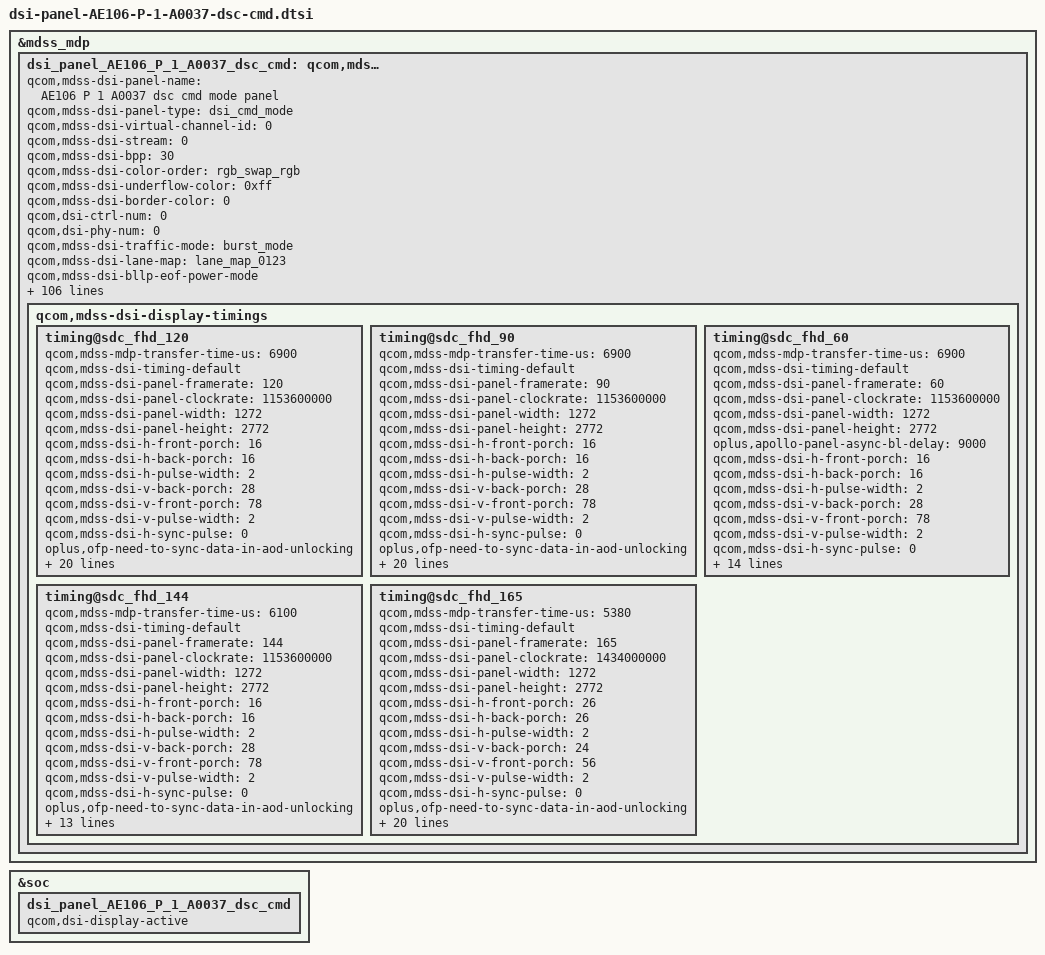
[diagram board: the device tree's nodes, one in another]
&mdss_mdp {
	dsi_panel_AE106_P_1_A0037_dsc_cmd: qcom,mdss_dsi_panel_AE106_P_1_A0037_dsc_cmd {
		qcom,mdss-dsi-panel-name = "AE106 P 1 A0037 dsc cmd mode panel";
		qcom,mdss-dsi-panel-type = "dsi_cmd_mode";
		qcom,mdss-dsi-virtual-channel-id = <0>;
		qcom,mdss-dsi-stream = <0>;
		qcom,mdss-dsi-bpp = <30>;
		qcom,mdss-dsi-color-order = "rgb_swap_rgb";
		qcom,mdss-dsi-underflow-color = <0xff>;
		qcom,mdss-dsi-border-color = <0>;
		qcom,dsi-ctrl-num = <0>;
		qcom,dsi-phy-num = <0>;
		qcom,mdss-dsi-traffic-mode = "burst_mode";
		qcom,mdss-dsi-lane-map = "lane_map_0123";
		qcom,mdss-dsi-bllp-eof-power-mode;
		qcom,mdss-dsi-bllp-power-mode;
		qcom,mdss-dsi-lane-0-state;
		qcom,mdss-dsi-lane-1-state;
		qcom,mdss-dsi-lane-2-state;
		qcom,mdss-dsi-lane-3-state;
		qcom,mdss-dsi-dma-trigger = "trigger_sw";
		qcom,mdss-dsi-dma-schedule-line = <1>;
		qcom,mdss-dsi-dma-schedule-window = <10>;
		qcom,mdss-dsi-mdp-trigger = "none";
		qcom,mdss-dsi-reset-sequence = <1 2>, <0 5>, <1 25>;
		qcom,mdss-dsi-te-pin-select = <1>;
		qcom,mdss-dsi-te-dcs-command = <1>;
		qcom,mdss-pan-physical-width-dimension = <71>;
		qcom,mdss-pan-physical-height-dimension = <157>;
		qcom,mdss-dsi-init-delay-us = <1000>;
		qcom,mdss-dsi-te-check-enable;
		qcom,mdss-dsi-te-using-te-pin;
		qcom,mdss-dsi-lp11-init;
		qcom,mdss-dsi-wr-mem-start = <0x2c>;
		qcom,mdss-dsi-wr-mem-continue = <0x3c>;
		qcom,mdss-dsi-panel-jitter = <0x4 0x1>;
		qcom,mdss-bl-high2bit;
		qcom,mdss-dsi-panel-skip-pps-update;
  		/* HDR Setting */
		qcom,mdss-dsi-panel-hdr-enabled;
		qcom,mdss-dsi-panel-hdr-color-primaries = <15635 16450 34000 16000 13250 34500 7500 3000>;
		//update for [MPC15]android.mediapc.cts.PerformanceClassTest#testDisplayHdr pass
		//qcom,mdss-dsi-panel-peak-brightness = <5400000>;
		qcom,mdss-dsi-panel-peak-brightness = <20000000>;
		qcom,mdss-dsi-panel-average-brightness = <2000000>;
		qcom,mdss-dsi-panel-blackness-level = <4000>;


		qcom,dynamic-mode-switch-enabled;
		qcom,dynamic-mode-switch-type = "dynamic-resolution-switch-immediate";
		qcom,mdss-dsi-display-timings {
			timing@sdc_fhd_120 {
				#include "dsi-panel-AE106-P-1-A0037-common.dtsi"
				#include "dsi-panel-AE106-P-1-A0037-common-effect.dtsi"
				qcom,mdss-mdp-transfer-time-us = <6900>;
				qcom,mdss-dsi-timing-default;
				qcom,mdss-dsi-panel-framerate = <120>;
				qcom,mdss-dsi-panel-clockrate = <1153600000>;
				qcom,mdss-dsi-panel-width = <1272>;
				qcom,mdss-dsi-panel-height = <2772>;

				qcom,mdss-dsi-h-front-porch = <16>;
				qcom,mdss-dsi-h-back-porch = <16>;
				qcom,mdss-dsi-h-pulse-width = <2>;
				qcom,mdss-dsi-v-back-porch = <28>;
				qcom,mdss-dsi-v-front-porch = <78>;
				qcom,mdss-dsi-v-pulse-width = <2>;
				qcom,mdss-dsi-h-sync-pulse = <0>;

				oplus,ofp-need-to-sync-data-in-aod-unlocking;
				oplus,ofp-aod-off-insert-black-frame = <1>;
				oplus,ofp-aod-off-black-frame-total-time = <42>;
				oplus,ofp-need-to-separate-backlight;
				oplus,ofp-backlight-on-period = <1>;

				qcom,mdss-dsi-timing-switch-command = [
				];
				qcom,mdss-dsi-fps-switch-60-to-120-command = [
					39 00 00 40 00 00 2D A9 01 00 44 26 27 00 00 01 00 44 28 2C 00 00 08 0B 18 02 01 C3 23 25 3F 5A 08 02 01 C3 26 27 3F 1A 02 01 C3 28 28 D4 02 01 C3 2E 2E 00
					39 00 00 40 00 00 B5 A9 02 08 E0 00 00 00 02 08 E1 02 02 20 02 08 E2 02 02 20 02 08 E1 10 10 24 02 08 E2 10 10 24 02 08 E1 1E 1E 1D 02 08 E2 1E 1E 1D 02 08 E1 2C 2C 18 02 08 E2 2C 2C 18 02 08 E1 3A 3A 10 02 08 E2 3A 3A 10 02 08 E3 3A 3A 04 02 08 E1 43 45 09 10 1A 02 08 E2 43 45 05 09 11 02 08 E3 43 45 05 0A 13 02 08 E1 48 48 08 02 08 E2 48 48 08 02 08 E3 48 48 04 02 08 E1 55 56 02 03 02 08 E2 56 56 04 02 08 E3 55 56 01 02 02 08 E1 64 64 03 02 08 E2 64 64 03 02 08 E3 62 64 01 02 03 02 08 E1 72 72 03 02 08 E2 72 72 03 02 08 E3 70 72 01 02 03 02 08 E0 00 00 01
					39 00 00 00 00 00 91 A9 01 00 68 00 00 00 02 01 DD 02 03 00 00 02 04 B5 01 03 00 00 03 01 00 9D 00 00 AA 02 08 B0 00 00 00 01 00 A2 00 47 13 02 09 BD 00 00 04 00 00 00 00 00 00 00 02 08 B7 20 27 08 00 08 00 07 B3 07 B3 02 08 B7 28 2D 07 CC 07 CC 08 00 00 00 02 08 B0 00 00 00 00 00 00 00 00 00 00 01 00 2F 00 00 00 00 00 00 00 00 00 00 02 01 B9 1C 1C 4A 01 00 8D 02 02 01 01 00 A3 00 0F 82 00 00 00 00 02 01 B9 1C 1C 4A 00 00 00 00 00 01 00 A3 10 11 00 00
				];
				qcom,mdss-dsi-fps-switch-90-to-120-command = [
					39 00 00 40 00 00 2D A9 01 00 44 26 27 00 00 01 00 44 28 2C 00 00 08 0B 18 02 01 C3 23 25 3F 5A 08 02 01 C3 26 27 3F 1A 02 01 C3 28 28 D4 02 01 C3 2E 2E 00
					39 00 00 40 00 00 B5 A9 02 08 E0 00 00 00 02 08 E1 02 02 20 02 08 E2 02 02 20 02 08 E1 10 10 24 02 08 E2 10 10 24 02 08 E1 1E 1E 1D 02 08 E2 1E 1E 1D 02 08 E1 2C 2C 18 02 08 E2 2C 2C 18 02 08 E1 3A 3A 10 02 08 E2 3A 3A 10 02 08 E3 3A 3A 04 02 08 E1 43 45 09 10 1A 02 08 E2 43 45 05 09 11 02 08 E3 43 45 05 0A 13 02 08 E1 48 48 08 02 08 E2 48 48 08 02 08 E3 48 48 04 02 08 E1 55 56 02 03 02 08 E2 56 56 04 02 08 E3 55 56 01 02 02 08 E1 64 64 03 02 08 E2 64 64 03 02 08 E3 62 64 01 02 03 02 08 E1 72 72 03 02 08 E2 72 72 03 02 08 E3 70 72 01 02 03 02 08 E0 00 00 01
					39 00 00 00 00 00 91 A9 01 00 68 00 00 00 02 01 DD 02 03 00 00 02 04 B5 01 03 00 00 03 01 00 9D 00 00 AA 02 08 B0 00 00 00 01 00 A2 00 47 13 02 09 BD 00 00 04 00 00 00 00 00 00 00 02 08 B7 20 27 08 00 08 00 07 B3 07 B3 02 08 B7 28 2D 07 CC 07 CC 08 00 00 00 02 08 B0 00 00 00 00 00 00 00 00 00 00 01 00 2F 00 00 00 00 00 00 00 00 00 00 02 01 B9 1C 1C 4A 01 00 8D 02 02 01 01 00 A3 00 0F 82 00 00 00 00 02 01 B9 1C 1C 4A 00 00 00 00 00 01 00 A3 10 11 00 00
				];
				qcom,mdss-dsi-fps-switch-144-to-120-command = [
					39 00 00 40 00 00 2D A9 01 00 44 26 27 00 00 01 00 44 28 2C 00 00 08 0B 18 02 01 C3 23 25 3F 5A 08 02 01 C3 26 27 3F 1A 02 01 C3 28 28 D4 02 01 C3 2E 2E 00
					39 00 00 40 00 00 B5 A9 02 08 E0 00 00 00 02 08 E1 02 02 20 02 08 E2 02 02 20 02 08 E1 10 10 24 02 08 E2 10 10 24 02 08 E1 1E 1E 1D 02 08 E2 1E 1E 1D 02 08 E1 2C 2C 18 02 08 E2 2C 2C 18 02 08 E1 3A 3A 10 02 08 E2 3A 3A 10 02 08 E3 3A 3A 04 02 08 E1 43 45 09 10 1A 02 08 E2 43 45 05 09 11 02 08 E3 43 45 05 0A 13 02 08 E1 48 48 08 02 08 E2 48 48 08 02 08 E3 48 48 04 02 08 E1 55 56 02 03 02 08 E2 56 56 04 02 08 E3 55 56 01 02 02 08 E1 64 64 03 02 08 E2 64 64 03 02 08 E3 62 64 01 02 03 02 08 E1 72 72 03 02 08 E2 72 72 03 02 08 E3 70 72 01 02 03 02 08 E0 00 00 01
					39 00 00 00 00 00 91 A9 01 00 68 00 00 00 02 01 DD 02 03 00 00 02 04 B5 01 03 00 00 03 01 00 9D 00 00 AA 02 08 B0 00 00 00 01 00 A2 00 47 13 02 09 BD 00 00 04 00 00 00 00 00 00 00 02 08 B7 20 27 08 00 08 00 07 B3 07 B3 02 08 B7 28 2D 07 CC 07 CC 08 00 00 00 02 08 B0 00 00 00 00 00 00 00 00 00 00 01 00 2F 00 00 00 00 00 00 00 00 00 00 02 01 B9 1C 1C 4A 01 00 8D 02 02 01 01 00 A3 00 0F 82 00 00 00 00 02 01 B9 1C 1C 4A 00 00 00 00 00 01 00 A3 10 11 00 00
				];
				qcom,mdss-dsi-fps-switch-165-to-120-command = [
					39 00 00 40 00 00 2D A9 01 00 44 26 27 00 00 01 00 44 28 2C 00 00 08 0B 18 02 01 C3 23 25 3F 5A 08 02 01 C3 26 27 3F 1A 02 01 C3 28 28 D4 02 01 C3 2E 2E 00
					39 00 00 40 00 00 B5 A9 02 08 E0 00 00 00 02 08 E1 02 02 20 02 08 E2 02 02 20 02 08 E1 10 10 24 02 08 E2 10 10 24 02 08 E1 1E 1E 1D 02 08 E2 1E 1E 1D 02 08 E1 2C 2C 18 02 08 E2 2C 2C 18 02 08 E1 3A 3A 10 02 08 E2 3A 3A 10 02 08 E3 3A 3A 04 02 08 E1 43 45 09 10 1A 02 08 E2 43 45 05 09 11 02 08 E3 43 45 05 0A 13 02 08 E1 48 48 08 02 08 E2 48 48 08 02 08 E3 48 48 04 02 08 E1 55 56 02 03 02 08 E2 56 56 04 02 08 E3 55 56 01 02 02 08 E1 64 64 03 02 08 E2 64 64 03 02 08 E3 62 64 01 02 03 02 08 E1 72 72 03 02 08 E2 72 72 03 02 08 E3 70 72 01 02 03 02 08 E0 00 00 01
					39 00 00 00 00 00 91 A9 01 00 68 00 00 00 02 01 DD 02 03 00 00 02 04 B5 01 03 00 00 03 01 00 9D 00 00 AA 02 08 B0 00 00 00 01 00 A2 00 47 13 02 09 BD 00 00 05 00 00 00 00 00 00 00 02 08 B7 20 27 08 00 08 00 07 B3 07 B3 02 08 B7 28 2D 07 CC 07 CC 08 00 00 00 02 08 B0 00 00 00 00 00 00 00 00 00 00 01 00 2F 00 00 00 00 00 00 00 00 00 00 02 01 B9 1C 1C 3A 01 00 8D 02 02 01 01 00 A3 00 0F 82 00 00 00 00 02 01 B9 1C 1C 4A 00 00 00 00 00 01 00 A3 10 11 00 00
				];
				qcom,mdss-dsi-on-command = [
					// Flash lock and reload
					39 00 00 40 00 00 06 F0 55 AA 52 08 04
					39 00 00 40 00 00 02 6F 03
					39 00 00 40 00 00 02 B5 0B
					39 00 00 40 00 00 02 C0 20
					39 00 00 40 00 00 02 C1 1C
					39 00 00 40 00 00 02 C0 80
					// DMR LUT SET
					39 00 00 40 00 00 02 C0 40
					39 00 00 40 00 00 06 F0 55 AA 52 08 00
					39 00 00 40 00 00 02 6F 31
					39 00 00 40 00 00 04 C0 01 02 10
					39 00 00 40 00 00 02 6F 08
					39 00 00 40 00 00 04 C7 98 97 80
					// APL BLK setting
					39 00 00 40 00 00 06 F0 55 AA 52 08 00
					39 00 00 40 00 00 02 6F 78
					39 00 00 40 00 00 18 B0 11 00 2A 00 C2 01 DA 03 7C 05 B1 08 80 0B EE 0F FF 05 55 05 56 05 55
					39 00 00 40 00 00 02 6F 6F
					39 00 00 40 00 00 07 B0 02 7C 04 F8 02 7C
					39 00 00 40 00 00 06 F0 55 AA 52 08 08
					39 00 00 40 00 00 17 C1 9D 4F DD 4F 4F DD 4F 4F DD 4F 4F DD 4F 4F BD 4F AC BB AC 9E 0D FF
					39 00 00 40 00 00 02 6F 1D
					39 00 00 40 00 00 04 C1 00 FF FF
					39 00 00 40 00 00 02 6F 20
					39 00 00 40 00 00 04 C1 3F 33 FF
					39 00 00 40 00 00 02 6F 23
					39 00 00 40 00 00 15 C1 0D 4F DD 4F 4F DD 4F 4F DD 4F 4F DD 4F 4F BD 4F AC BB AC 9E
					39 00 00 40 00 00 02 6F 37
					39 00 00 40 00 00 15 C1 0E FF EE FF FF EE FF FF EE FF FF EE FF FF DE FF 27 DD 27 27
					39 00 00 40 00 00 02 6F 4B
					39 00 00 40 00 00 15 C1 0D 4F DD 4F 4F DD 4F 4F DD 4F 4F DD 4F 4F BD 4F AC BB AC 9E
					39 00 00 40 00 00 02 6F 5F
					39 00 00 40 00 00 15 C1 0F FF FF FF FF FF FF FF FF FF FF FF FF FF FF FF FF FF FF FF
					39 00 00 40 00 00 02 6F 73
					39 00 00 40 00 00 15 C1 0D 4F DD 4F 4F DD 4F 4F DD 4F 4F DD 4F 4F BD 4F AC BB AC 9E
					39 00 00 40 00 00 2D BA 00 01 00 8A 00 8A 01 1E 01 1E 01 9D 01 9D 02 44 02 44 03 25 03 25 04 02 04 02 04 13 04 13 06 98 06 98 0A E2 0A E2 0D BB 0D BB 0F FE
					39 00 00 40 00 00 02 6F 07
					39 00 00 40 00 00 02 51 00
					39 00 00 40 00 00 05 FF AA 55 A5 80
					// Power on/off sequence related
					39 00 00 40 00 00 02 6F 08
					39 00 00 40 00 00 02 F6 54
					39 00 00 40 00 00 02 6F 0A
					39 00 00 40 00 00 07 F6 70 70 70 70 70 70
					// DMR flashing optimization
					39 00 00 40 00 00 05 FF AA 55 A5 81
					39 00 00 40 00 00 02 6F 0D
					39 00 00 40 00 00 02 FD 40
					// Charge Pump from 2uA to 4uA
					39 00 00 40 00 00 05 FF AA 55 A5 80
					39 00 00 40 00 00 02 6F 07
					39 00 00 40 00 00 02 F8 4D
					39 00 00 40 00 00 02 6F 23
					39 00 00 40 00 00 02 F8 4D
					// TE ON
					39 00 00 40 00 00 02 35 00
					//TE1F ON
					39 00 00 40 00 00 02 6F 15
					39 00 00 40 00 00 02 35 60
					39 00 00 40 00 00 02 6F 26
					39 00 00 40 00 00 08 44 00 00 00 00 08 0B 18
					// BC Dimming OFF
					39 00 00 40 00 00 02 53 20
					// Normal DBV setting
					39 00 00 40 00 00 03 51 00 00
					// Idle DBV Setting
					39 00 00 40 00 00 02 6F 04
					39 00 00 40 00 00 03 51 0D DA
					// H_res = 1272  V_res = 2772
					39 00 00 40 00 00 05 2A 00 00 04 F7
					39 00 00 40 00 00 05 2B 00 00 0A D3
					// Compression method selection 10_8 2dsc & slice high 12 & vesa 1.2
					39 00 00 40 00 00 02 90 03
					39 00 00 40 00 00 02 6F 01
					39 00 00 40 00 00 02 90 43
					39 00 00 40 00 00 13 91 AB A8 00 0C C2 00 02 3E 01 37 00 08 08 BB 07 32 10 F0
					// GPIO Setting
					39 00 00 40 00 00 06 F0 55 AA 52 08 00
					39 00 00 40 00 00 05 BE 5F 4C 47 49
					// Round curve control
					39 00 00 40 00 00 06 F0 55 AA 52 08 07
					39 00 00 40 00 00 0E B8 01 00 F5 09 C8 00 00 00 00 00 00 00 00
					39 00 00 40 00 00 04 C0 A7 01 09
					39 00 00 40 00 00 02 6F 03
					39 00 00 40 00 00 05 C0 00 00 00 00
					39 00 00 40 00 00 16 C1 B0 0F 00 24 09 00 FD C0 3F FF DD B0 3F FE 6D 28 00 00 08 2D 10
					39 00 00 40 00 00 02 6F 15
					39 00 00 40 00 00 11 C1 06 01 94 0E 00 00 06 33 F0 FA 86 02 DC 00 00 00
					39 00 00 40 00 00 02 6F 25
					39 00 00 40 00 00 08 C1 00 00 05 00 8A 98 00
					39 00 00 40 00 00 16 C2 B0 0F 26 49 29 71 B0 56 3F C1 8B B2 3F C0 4D 0A 00 17 08 B0 2C
					39 00 00 40 00 00 02 6F 15
					39 00 00 40 00 00 11 C2 3D 00 06 93 00 05 97 43 F0 6F 73 4F DD C0 00 FF
					39 00 00 40 00 00 02 6F 25
					39 00 00 40 00 00 08 C2 00 90 93 00 00 05 00
					39 00 00 40 00 00 16 C3 B8 0F 05 A4 00 10 FE D0 3F FF 44 E0 3F FF F0 28 00 00 03 97 B0
					39 00 00 40 00 00 02 6F 15
					39 00 00 40 00 00 11 C3 5A 00 00 06 00 98 F2 33 F0 A6 FA 02 1C 00 00 00
					39 00 00 40 00 00 02 6F 25
					39 00 00 40 00 00 08 C3 44 64 67 00 00 05 00
					39 00 00 40 00 00 16 C4 BC 00 13 24 00 40 04 60 3F FB 1E 00 00 00 00 00 00 00 00 00 00
					39 00 00 40 00 00 02 6F 15
					39 00 00 40 00 00 11 C4 82 00 00 08 9A CB 4D 33 C0 7E 08 00 00 00 00 00
					39 00 00 40 00 00 02 6F 25
					39 00 00 40 00 00 08 C4 44 F2 F7 00 91 97 00
					39 00 00 40 00 00 16 C5 BC 00 17 C4 1A E9 32 94 3F BD 81 A4 00 10 C8 E8 00 00 00 00 00
					39 00 00 40 00 00 02 6F 15
					39 00 00 40 00 00 11 C5 50 00 08 8F AA 4E CE 33 C0 80 87 00 00 00 00 00
					39 00 00 40 00 00 02 6F 25
					39 00 00 40 00 00 08 C5 00 01 07 AA 4D 57 00
					39 00 00 40 00 00 16 C6 B4 00 00 01 01 B9 00 2A 3F FF FC 58 00 00 12 48 00 00 00 00 00
					39 00 00 40 00 00 02 6F 15
					39 00 00 40 00 00 11 C6 05 00 90 C3 AA CE D3 33 C0 FB 33 00 00 00 00 00
					39 00 00 40 00 00 02 6F 25
					39 00 00 40 00 00 08 C6 00 88 90 AA CF D3 00
					39 00 00 40 00 00 16 C7 31 00 05 A4 05 A4 00 00 3F FE 53 50 3F FE 53 50 00 00 1F D1 10
					39 00 00 40 00 00 02 6F 15
					39 00 00 40 00 00 11 C7 0B 22 55 7B 00 2C 52 33 F0 DA DA 05 A4 00 00 00
					39 00 00 40 00 00 02 6F 25
					39 00 00 40 00 00 08 C7 44 F0 F7 AA 4D 54 00
					39 00 00 40 00 00 16 C8 3D 00 05 A4 05 A4 00 00 3F FE 53 50 00 00 00 00 00 00 00 00 00
					39 00 00 40 00 00 02 6F 15
					39 00 00 40 00 00 11 C8 1A 22 55 7B 00 53 79 33 C0 DA 26 00 00 00 00 00
					39 00 00 40 00 00 02 6F 25
					39 00 00 40 00 00 08 C8 44 69 70 AA CF D3 00
					39 00 00 40 00 00 16 C9 27 00 05 A4 05 A4 00 00 00 00 00 00 3F FE 53 50 00 00 00 00 00
					39 00 00 40 00 00 02 6F 15
					39 00 00 40 00 00 11 C9 0B 22 7C A2 00 2C 52 33 30 26 DA 00 00 00 00 00
					39 00 00 40 00 00 02 6F 25
					39 00 00 40 00 00 08 C9 00 00 00 00 00 00 00
					39 00 00 40 00 00 16 CA 2B 00 05 A4 05 A4 00 00 00 00 00 00 00 00 00 00 7F FF E0 2E F0
					39 00 00 40 00 00 02 6F 15
					39 00 00 40 00 00 11 CA 1A 22 7C A2 00 53 79 33 0F 26 26 FA 5C 00 00 00
					39 00 00 40 00 00 02 6F 25
					39 00 00 40 00 00 08 CA 00 00 00 00 00 00 00
					39 00 00 40 00 00 16 CB 00 00 00 00 00 00 00 00 00 00 00 00 00 00 00 00 00 00 00 00 00
					39 00 00 40 00 00 02 6F 15
					39 00 00 40 00 00 11 CB 00 00 00 00 00 00 00 00 00 00 00 00 00 00 00 00
					39 00 00 40 00 00 02 6F 25
					39 00 00 40 00 00 08 CB 00 00 00 00 00 00 00
					39 00 00 40 00 00 16 CC 00 00 00 00 00 00 00 00 00 00 00 00 00 00 00 00 00 00 00 00 00
					39 00 00 40 00 00 02 6F 15
					39 00 00 40 00 00 11 CC 00 00 00 00 00 00 00 00 00 00 00 00 00 00 00 00
					39 00 00 40 00 00 02 6F 25
					39 00 00 40 00 00 08 CC 00 00 00 00 00 00 00
					39 00 00 40 00 00 16 CD 00 00 00 00 00 00 00 00 00 00 00 00 00 00 00 00 00 00 00 00 00
					39 00 00 40 00 00 02 6F 15
					39 00 00 40 00 00 11 CD 00 00 00 00 00 00 00 00 00 00 00 00 00 00 00 00
					39 00 00 40 00 00 02 6F 25
					39 00 00 40 00 00 08 CD 00 00 00 00 00 00 00
					39 00 00 40 00 00 16 CE 00 00 00 00 00 00 00 00 00 00 00 00 00 00 00 00 00 00 00 00 00
					39 00 00 40 00 00 02 6F 15
					39 00 00 40 00 00 11 CE 00 00 00 00 00 00 00 00 00 00 00 00 00 00 00 00
					39 00 00 40 00 00 02 6F 25
					39 00 00 40 00 00 08 CE 00 00 00 00 00 00 00
					39 00 00 40 00 00 16 CF 00 00 00 00 00 00 00 00 00 00 00 00 00 00 00 00 00 00 00 00 00
					39 00 00 40 00 00 02 6F 15
					39 00 00 40 00 00 11 CF 00 00 00 00 00 00 00 00 00 00 00 00 00 00 00 00
					39 00 00 40 00 00 02 6F 25
					39 00 00 40 00 00 08 CF 00 00 00 00 00 00 00
					39 00 00 40 00 00 16 D0 00 00 00 00 00 00 00 00 00 00 00 00 00 00 00 00 00 00 00 00 00
					39 00 00 40 00 00 02 6F 15
					39 00 00 40 00 00 11 D0 00 00 00 00 00 00 00 00 00 00 00 00 00 00 00 00
					39 00 00 40 00 00 02 6F 25
					39 00 00 40 00 00 08 D0 00 00 00 00 00 00 00
					39 00 00 40 00 00 0F D1 80 00 00 00 00 04 F8 80 00 6B BD 09 04 F7
					39 00 00 40 00 00 02 6F 0E
					39 00 00 40 00 00 0F D1 80 00 00 00 00 04 F7 FF FF DD B9 00 04 F7
					39 00 00 40 00 00 02 6F 1C
					39 00 00 40 00 00 0F D1 FF E3 8B 46 00 04 F7 FF FF FF 4F B1 04 F8
					39 00 00 40 00 00 02 6F 2A
					39 00 00 40 00 00 0C D1 00 00 00 00 00 04 F8 7F FF E0 2E
					39 00 00 40 00 00 12 D2 F0 04 F8 00 00 1F D1 10 04 F8 00 00 00 00 00 04 F8
					//RCN
					39 00 00 40 00 00 06 F0 55 AA 52 08 07
					39 00 00 40 00 00 02 C0 A7
					//OSC trim
					39 00 00 40 00 00 06 F0 55 AA 52 08 01
					39 00 00 40 00 00 36 C3 99 29 02 6B 19 00 29 00 6B 19 00 3F 5A 08 3F 1A D4 3F 2A 07 3F 28 D4 3F 25 06 3F 61 D4 3F 3B 46 3F 46 07 3F 5A 08 3F 1A D4 11 11 01 00 10 00 77 00 AA 02 AA 02
					39 00 00 40 00 00 06 F0 55 AA 52 08 01
					39 00 00 40 00 00 07 B3 44 44 44 44 44 44
					39 00 00 40 00 00 06 F0 55 AA 52 08 07
					39 00 00 40 00 00 0E B4 C0 50 60 60 50 35 80 20 60 58 80 38 70
					//OD
					39 00 00 40 00 00 06 F0 55 AA 52 08 08
					39 00 00 40 00 00 05 E0 01 01 81 01
					39 00 00 40 00 00 02 6F 06
					39 00 00 40 00 00 0E E0 80 00 21 32 43 54 65 66 66 76 87 98 99
					39 00 00 40 00 00 06 F0 55 AA 52 08 08
					39 00 00 40 00 00 02 6F 04
					39 00 00 40 00 00 02 E0 20
					39 00 00 40 00 00 02 6F 1B
					39 00 00 40 00 00 04 EB 44 00 00
					39 00 00 40 00 00 02 6F 1E
					39 00 00 40 00 00 04 EB 94 00 00
					39 00 00 40 00 00 02 6F 21
					39 00 00 40 00 00 03 EB 04 00
					39 00 00 40 00 00 02 6F 24
					39 00 00 40 00 00 04 EB 10 32 54
					39 00 00 40 00 00 0F E1 03 04 20 00 00 00 00 00 00 00 00 00 00 00
					39 00 00 40 00 00 0F E2 03 04 20 00 00 00 00 00 00 00 00 00 00 00
					39 00 00 40 00 00 0F E3 00 00 00 00 00 00 00 00 00 00 00 00 00 00
					39 00 00 40 00 00 02 6F 0E
					39 00 00 40 00 00 0F E1 02 04 24 03 03 03 03 03 03 03 03 08 0F 1A
					39 00 00 40 00 00 02 6F 0E
					39 00 00 40 00 00 0F E2 03 04 24 03 03 03 03 03 03 03 03 09 0E 17
					39 00 00 40 00 00 02 6F 0E
					39 00 00 40 00 00 0F E3 03 04 06 03 03 03 03 03 03 04 03 09 0E 07
					39 00 00 40 00 00 02 6F 1C
					39 00 00 40 00 00 0F E1 01 03 1D 03 03 03 03 03 03 03 03 03 08 0F
					39 00 00 40 00 00 02 6F 1C
					39 00 00 40 00 00 0F E2 02 03 1D 04 04 04 04 04 04 04 04 04 07 0C
					39 00 00 40 00 00 02 6F 1C
					39 00 00 40 00 00 0F E3 02 03 05 04 04 04 04 04 04 04 04 03 07 12
					39 00 00 40 00 00 02 6F 2A
					39 00 00 40 00 00 0F E1 01 03 18 04 04 04 04 04 04 04 04 04 07 0E
					39 00 00 40 00 00 02 6F 2A
					39 00 00 40 00 00 0F E2 02 03 18 03 03 03 03 03 03 03 03 03 06 0D
					39 00 00 40 00 00 02 6F 2A
					39 00 00 40 00 00 0F E3 01 01 04 03 03 03 03 03 03 03 03 05 0B 13
					39 00 00 40 00 00 02 6F 38
					39 00 00 40 00 00 0F E1 02 04 10 04 04 04 04 04 04 04 04 09 10 1A
					39 00 00 40 00 00 02 6F 38
					39 00 00 40 00 00 0F E2 03 04 10 04 04 04 04 04 04 04 04 05 09 11
					39 00 00 40 00 00 02 6F 38
					39 00 00 40 00 00 0F E3 01 01 04 04 04 04 04 04 04 04 05 05 0A 13
					39 00 00 40 00 00 02 6F 46
					39 00 00 40 00 00 0F E1 02 04 08 03 03 03 03 03 05 05 05 05 05 10
					39 00 00 40 00 00 02 6F 46
					39 00 00 40 00 00 0F E2 03 04 08 03 03 03 03 03 04 04 04 04 04 06
					39 00 00 40 00 00 02 6F 46
					39 00 00 40 00 00 0F E3 01 01 04 03 03 03 03 03 04 04 04 04 04 06
					39 00 00 40 00 00 02 6F 54
					39 00 00 40 00 00 0F E1 01 02 03 04 05 05 05 03 03 03 02 02 02 02
					39 00 00 40 00 00 02 6F 54
					39 00 00 40 00 00 0F E2 01 02 04 04 04 05 05 02 02 01 01 01 01 01
					39 00 00 40 00 00 02 6F 54
					39 00 00 40 00 00 0F E3 00 01 02 02 04 05 05 02 02 01 01 01 01 01
					39 00 00 40 00 00 02 6F 62
					39 00 00 40 00 00 0F E1 01 02 03 04 04 04 04 03 03 03 02 02 02 02
					39 00 00 40 00 00 02 6F 62
					39 00 00 40 00 00 0F E2 01 02 03 03 03 03 03 02 02 01 01 01 01 01
					39 00 00 40 00 00 02 6F 62
					39 00 00 40 00 00 0F E3 01 02 03 03 03 03 03 02 02 01 01 01 01 01
					39 00 00 40 00 00 02 6F 70
					39 00 00 40 00 00 0F E1 01 02 03 04 04 04 04 03 03 03 02 02 02 02
					39 00 00 40 00 00 02 6F 70
					39 00 00 40 00 00 0F E2 01 02 03 04 05 04 04 02 02 02 01 01 01 01
					39 00 00 40 00 00 02 6F 70
					39 00 00 40 00 00 0F E3 01 02 03 04 05 04 04 02 02 02 01 01 01 01
					// Sleep out
					15 00 00 00 78 00 02 11 00
					// Display on
					15 00 00 00 00 00 02 29 00
					39 00 00 40 00 00 02 68 00
					39 00 00 40 00 00 06 F0 55 AA 52 08 00
					39 00 00 40 00 00 02 6F 04
					39 00 00 40 00 00 02 B1 00
					39 00 00 40 00 00 02 6F 2A
					39 00 00 40 00 00 02 BB 00
					39 00 00 40 00 00 02 6F 30
					39 00 00 40 00 00 02 C0 3F
					39 00 00 40 00 00 06 F0 55 AA 52 08 09
					39 00 00 40 00 00 02 BD 04
					39 00 00 40 00 00 02 6F 01
					39 00 00 40 00 00 0A BD 31 9D 25 54 13 14 A6 98 E2
					39 00 00 40 00 00 02 6F 0A
					39 00 00 40 00 00 06 BD 10 20 40 80 FF
					39 00 00 40 00 00 02 6F 1A
					39 00 00 40 00 00 06 BD FF FF FF FF FF
					39 00 00 40 00 00 02 6F 10
					39 00 00 40 00 00 04 BD FD 07 00
					39 00 00 40 00 00 02 6F 16
					39 00 00 40 00 00 02 BD 15
					39 00 00 40 00 00 06 F0 55 AA 52 08 09
					39 00 00 40 00 00 02 6F 00
					39 00 00 40 00 00 1F BE 19 14 0A 23 1E 05 05 00 05 0A 01 01 03 06 82 00 02 02 00 09 81 02 80 88 0B 01 00 00 07 81
					39 00 00 40 00 00 02 6F 1E
					39 00 00 40 00 00 1F BE 19 14 0A 23 1E 05 05 00 05 0A 01 01 03 06 82 00 02 02 00 09 81 02 80 88 0B 01 00 00 07 81
					39 00 00 40 00 00 02 6F 3C
					39 00 00 40 00 00 1F BE 19 14 0A 23 1E 05 05 00 05 0A 01 01 03 06 82 00 02 02 00 09 81 02 80 88 0B 01 00 00 07 81
					39 00 00 40 00 00 06 F0 55 AA 52 08 09
					39 00 00 40 00 00 02 6F 00
					39 00 00 40 00 00 1F BF 19 18 0C 18 2C 08 02 02 0A 04 04 04 10 08 14 01 04 06 00 0C 00 00 04 89 88 02 02 05 02 0A
					39 00 00 40 00 00 02 6F 1E
					39 00 00 40 00 00 1F BF 19 18 0C 18 2C 08 02 02 0A 04 04 04 10 08 14 01 04 06 00 0C 00 00 04 89 88 02 02 05 02 0A
					39 00 00 40 00 00 02 6F 3C
					39 00 00 40 00 00 1F BF 19 18 0C 18 2C 08 02 02 0A 04 04 04 10 08 14 01 04 06 00 0C 00 00 04 89 88 02 02 05 02 0A
					// 120Hz Freq. Setting
					39 00 00 40 00 00 2D A9 01 00 44 26 27 00 00 01 00 44 28 2C 00 00 08 0B 18 02 01 C3 23 25 3F 5A 08 02 01 C3 26 27 3F 1A 02 01 C3 28 28 D4 02 01 C3 2E 2E 00
					39 00 00 40 00 00 B5 A9 02 08 E0 00 00 00 02 08 E1 02 02 20 02 08 E2 02 02 20 02 08 E1 10 10 24 02 08 E2 10 10 24 02 08 E1 1E 1E 1D 02 08 E2 1E 1E 1D 02 08 E1 2C 2C 18 02 08 E2 2C 2C 18 02 08 E1 3A 3A 10 02 08 E2 3A 3A 10 02 08 E3 3A 3A 04 02 08 E1 43 45 09 10 1A 02 08 E2 43 45 05 09 11 02 08 E3 43 45 05 0A 13 02 08 E1 48 48 08 02 08 E2 48 48 08 02 08 E3 48 48 04 02 08 E1 55 56 02 03 02 08 E2 56 56 04 02 08 E3 55 56 01 02 02 08 E1 64 64 03 02 08 E2 64 64 03 02 08 E3 62 64 01 02 03 02 08 E1 72 72 03 02 08 E2 72 72 03 02 08 E3 70 72 01 02 03 02 08 E0 00 00 01
					39 00 00 00 00 00 91 A9 01 00 68 00 00 00 02 01 DD 02 03 00 00 02 04 B5 01 03 00 00 03 01 00 9D 00 00 AA 02 08 B0 00 00 00 01 00 A2 00 47 13 02 09 BD 00 00 04 00 00 00 00 00 00 00 02 08 B7 20 27 08 00 08 00 07 B3 07 B3 02 08 B7 28 2D 07 CC 07 CC 08 00 00 00 02 08 B0 00 00 00 00 00 00 00 00 00 00 01 00 2F 00 00 00 00 00 00 00 00 00 00 02 01 B9 1C 1C 4A 01 00 8D 02 02 01 01 00 A3 00 0F 82 00 00 00 00 02 01 B9 1C 1C 4A 00 00 00 00 00 01 00 A3 10 11 00 00
				];

			};
			timing@sdc_fhd_90 {
				#include "dsi-panel-AE106-P-1-A0037-common.dtsi"
				#include "dsi-panel-AE106-P-1-A0037-common-effect.dtsi"
				qcom,mdss-mdp-transfer-time-us = <6900>;
				qcom,mdss-dsi-timing-default;
				qcom,mdss-dsi-panel-framerate = <90>;
				qcom,mdss-dsi-panel-clockrate = <1153600000>;
				qcom,mdss-dsi-panel-width = <1272>;
				qcom,mdss-dsi-panel-height = <2772>;

				qcom,mdss-dsi-h-front-porch = <16>;
				qcom,mdss-dsi-h-back-porch = <16>;
				qcom,mdss-dsi-h-pulse-width = <2>;
				qcom,mdss-dsi-v-back-porch = <28>;
				qcom,mdss-dsi-v-front-porch = <78>;
				qcom,mdss-dsi-v-pulse-width = <2>;
				qcom,mdss-dsi-h-sync-pulse = <0>;

				oplus,ofp-need-to-sync-data-in-aod-unlocking;
				oplus,ofp-aod-off-insert-black-frame = <1>;
				oplus,ofp-aod-off-black-frame-total-time = <42>;
				oplus,ofp-need-to-separate-backlight;
				oplus,ofp-backlight-on-period = <1>;

				qcom,mdss-dsi-timing-switch-command = [
				];
				qcom,mdss-dsi-fps-switch-60-to-90-command = [
					39 00 00 40 00 00 2D A9 01 00 44 26 27 00 00 01 00 44 28 2C 00 00 08 07 60 02 01 C3 23 25 3F 2A 07 02 01 C3 26 27 3F 28 02 01 C3 28 28 D4 02 01 C3 2E 2E 00
					39 00 00 40 00 00 B5 A9 02 08 E0 00 00 00 02 08 E1 02 02 20 02 08 E2 02 02 20 02 08 E1 10 10 24 02 08 E2 10 10 24 02 08 E1 1E 1E 1D 02 08 E2 1E 1E 1D 02 08 E1 2C 2C 18 02 08 E2 2C 2C 18 02 08 E1 3A 3A 10 02 08 E2 3A 3A 10 02 08 E3 3A 3A 04 02 08 E1 43 45 09 10 1A 02 08 E2 43 45 05 09 11 02 08 E3 43 45 05 0A 13 02 08 E1 48 48 08 02 08 E2 48 48 08 02 08 E3 48 48 04 02 08 E1 55 56 02 03 02 08 E2 56 56 04 02 08 E3 55 56 01 02 02 08 E1 64 64 03 02 08 E2 64 64 03 02 08 E3 62 64 01 02 03 02 08 E1 72 72 03 02 08 E2 72 72 03 02 08 E3 70 72 01 02 03 02 08 E0 00 00 01
					39 00 00 00 00 00 91 A9 01 00 68 00 00 00 02 01 DD 02 03 00 00 02 04 B5 01 03 00 00 03 01 00 9D 00 00 AA 02 08 B0 00 00 00 01 00 A2 00 47 13 02 09 BD 00 00 04 00 00 00 00 00 00 00 02 08 B7 20 27 08 00 08 00 07 B3 07 B3 02 08 B7 28 2D 07 CC 07 CC 08 00 00 00 02 08 B0 00 00 00 00 00 00 00 00 00 00 01 00 2F 00 00 01 00 00 00 00 00 00 00 02 01 B9 1D 1D 4A 01 00 8D 02 02 01 01 00 A3 00 0F 82 00 00 00 00 02 01 B9 1D 1D 4A 00 00 00 00 00 01 00 A3 10 11 00 00
				];
				qcom,mdss-dsi-fps-switch-120-to-90-command = [
					39 00 00 40 00 00 2D A9 01 00 44 26 27 00 00 01 00 44 28 2C 00 00 08 07 60 02 01 C3 23 25 3F 2A 07 02 01 C3 26 27 3F 28 02 01 C3 28 28 D4 02 01 C3 2E 2E 00
					39 00 00 40 00 00 B5 A9 02 08 E0 00 00 00 02 08 E1 02 02 20 02 08 E2 02 02 20 02 08 E1 10 10 24 02 08 E2 10 10 24 02 08 E1 1E 1E 1D 02 08 E2 1E 1E 1D 02 08 E1 2C 2C 18 02 08 E2 2C 2C 18 02 08 E1 3A 3A 10 02 08 E2 3A 3A 10 02 08 E3 3A 3A 04 02 08 E1 43 45 09 10 1A 02 08 E2 43 45 05 09 11 02 08 E3 43 45 05 0A 13 02 08 E1 48 48 08 02 08 E2 48 48 08 02 08 E3 48 48 04 02 08 E1 55 56 02 03 02 08 E2 56 56 04 02 08 E3 55 56 01 02 02 08 E1 64 64 03 02 08 E2 64 64 03 02 08 E3 62 64 01 02 03 02 08 E1 72 72 03 02 08 E2 72 72 03 02 08 E3 70 72 01 02 03 02 08 E0 00 00 01
					39 00 00 00 00 00 91 A9 01 00 68 00 00 00 02 01 DD 02 03 00 00 02 04 B5 01 03 00 00 03 01 00 9D 00 00 AA 02 08 B0 00 00 00 01 00 A2 00 47 13 02 09 BD 00 00 04 00 00 00 00 00 00 00 02 08 B7 20 27 08 00 08 00 07 B3 07 B3 02 08 B7 28 2D 07 CC 07 CC 08 00 00 00 02 08 B0 00 00 00 00 00 00 00 00 00 00 01 00 2F 00 00 01 00 00 00 00 00 00 00 02 01 B9 1D 1D 4A 01 00 8D 02 02 01 01 00 A3 00 0F 82 00 00 00 00 02 01 B9 1D 1D 4A 00 00 00 00 00 01 00 A3 10 11 00 00
				];
				qcom,mdss-dsi-fps-switch-144-to-90-command = [
					39 00 00 40 00 00 2D A9 01 00 44 26 27 00 00 01 00 44 28 2C 00 00 08 07 60 02 01 C3 23 25 3F 2A 07 02 01 C3 26 27 3F 28 02 01 C3 28 28 D4 02 01 C3 2E 2E 00
					39 00 00 40 00 00 B5 A9 02 08 E0 00 00 00 02 08 E1 02 02 20 02 08 E2 02 02 20 02 08 E1 10 10 24 02 08 E2 10 10 24 02 08 E1 1E 1E 1D 02 08 E2 1E 1E 1D 02 08 E1 2C 2C 18 02 08 E2 2C 2C 18 02 08 E1 3A 3A 10 02 08 E2 3A 3A 10 02 08 E3 3A 3A 04 02 08 E1 43 45 09 10 1A 02 08 E2 43 45 05 09 11 02 08 E3 43 45 05 0A 13 02 08 E1 48 48 08 02 08 E2 48 48 08 02 08 E3 48 48 04 02 08 E1 55 56 02 03 02 08 E2 56 56 04 02 08 E3 55 56 01 02 02 08 E1 64 64 03 02 08 E2 64 64 03 02 08 E3 62 64 01 02 03 02 08 E1 72 72 03 02 08 E2 72 72 03 02 08 E3 70 72 01 02 03 02 08 E0 00 00 01
					39 00 00 00 00 00 91 A9 01 00 68 00 00 00 02 01 DD 02 03 00 00 02 04 B5 01 03 00 00 03 01 00 9D 00 00 AA 02 08 B0 00 00 00 01 00 A2 00 47 13 02 09 BD 00 00 04 00 00 00 00 00 00 00 02 08 B7 20 27 08 00 08 00 07 B3 07 B3 02 08 B7 28 2D 07 CC 07 CC 08 00 00 00 02 08 B0 00 00 00 00 00 00 00 00 00 00 01 00 2F 00 00 01 00 00 00 00 00 00 00 02 01 B9 1D 1D 4A 01 00 8D 02 02 01 01 00 A3 00 0F 82 00 00 00 00 02 01 B9 1D 1D 4A 00 00 00 00 00 01 00 A3 10 11 00 00
				];
				qcom,mdss-dsi-fps-switch-165-to-90-command = [
					39 00 00 40 00 00 2D A9 01 00 44 26 27 00 00 01 00 44 28 2C 00 00 08 07 60 02 01 C3 23 25 3F 2A 07 02 01 C3 26 27 3F 28 02 01 C3 28 28 D4 02 01 C3 2E 2E 00
					39 00 00 40 00 00 B5 A9 02 08 E0 00 00 00 02 08 E1 02 02 20 02 08 E2 02 02 20 02 08 E1 10 10 24 02 08 E2 10 10 24 02 08 E1 1E 1E 1D 02 08 E2 1E 1E 1D 02 08 E1 2C 2C 18 02 08 E2 2C 2C 18 02 08 E1 3A 3A 10 02 08 E2 3A 3A 10 02 08 E3 3A 3A 04 02 08 E1 43 45 09 10 1A 02 08 E2 43 45 05 09 11 02 08 E3 43 45 05 0A 13 02 08 E1 48 48 08 02 08 E2 48 48 08 02 08 E3 48 48 04 02 08 E1 55 56 02 03 02 08 E2 56 56 04 02 08 E3 55 56 01 02 02 08 E1 64 64 03 02 08 E2 64 64 03 02 08 E3 62 64 01 02 03 02 08 E1 72 72 03 02 08 E2 72 72 03 02 08 E3 70 72 01 02 03 02 08 E0 00 00 01
					39 00 00 00 00 00 91 A9 01 00 68 00 00 30 02 01 DD 02 03 00 00 02 04 B5 01 03 00 00 03 01 00 9D 00 00 AA 02 08 B0 00 00 00 01 00 A2 00 47 13 02 09 BD 00 00 05 00 00 00 00 00 00 00 02 08 B7 20 27 08 00 08 00 07 B3 07 B3 02 08 B7 28 2D 07 CC 07 CC 08 00 00 00 02 08 B0 00 00 00 00 00 00 00 00 00 00 01 00 2F 00 00 01 00 00 00 00 00 00 00 02 01 B9 1D 1D 3A 01 00 8D 02 02 01 01 00 A3 00 0F 82 00 00 00 00 02 01 B9 1D 1D 4A 00 00 00 00 00 01 00 A3 10 11 00 00
				];
				qcom,mdss-dsi-on-command = [
					// Flash lock and reload
					39 00 00 40 00 00 06 F0 55 AA 52 08 04
					39 00 00 40 00 00 02 6F 03
					39 00 00 40 00 00 02 B5 0B
					39 00 00 40 00 00 02 C0 20
					39 00 00 40 00 00 02 C1 1C
					39 00 00 40 00 00 02 C0 80
					// DMR LUT SET
					39 00 00 40 00 00 02 C0 40
					39 00 00 40 00 00 06 F0 55 AA 52 08 00
					39 00 00 40 00 00 02 6F 31
					39 00 00 40 00 00 04 C0 01 02 10
					39 00 00 40 00 00 02 6F 08
					39 00 00 40 00 00 04 C7 98 97 80
					// APL BLK setting
					39 00 00 40 00 00 06 F0 55 AA 52 08 00
					39 00 00 40 00 00 02 6F 78
					39 00 00 40 00 00 18 B0 11 00 2A 00 C2 01 DA 03 7C 05 B1 08 80 0B EE 0F FF 05 55 05 56 05 55
					39 00 00 40 00 00 02 6F 6F
					39 00 00 40 00 00 07 B0 02 7C 04 F8 02 7C
					39 00 00 40 00 00 06 F0 55 AA 52 08 08
					39 00 00 40 00 00 17 C1 9D 4F DD 4F 4F DD 4F 4F DD 4F 4F DD 4F 4F BD 4F AC BB AC 9E 0D FF
					39 00 00 40 00 00 02 6F 1D
					39 00 00 40 00 00 04 C1 00 FF FF
					39 00 00 40 00 00 02 6F 20
					39 00 00 40 00 00 04 C1 3F 33 FF
					39 00 00 40 00 00 02 6F 23
					39 00 00 40 00 00 15 C1 0D 4F DD 4F 4F DD 4F 4F DD 4F 4F DD 4F 4F BD 4F AC BB AC 9E
					39 00 00 40 00 00 02 6F 37
					39 00 00 40 00 00 15 C1 0E FF EE FF FF EE FF FF EE FF FF EE FF FF DE FF 27 DD 27 27
					39 00 00 40 00 00 02 6F 4B
					39 00 00 40 00 00 15 C1 0D 4F DD 4F 4F DD 4F 4F DD 4F 4F DD 4F 4F BD 4F AC BB AC 9E
					39 00 00 40 00 00 02 6F 5F
					39 00 00 40 00 00 15 C1 0F FF FF FF FF FF FF FF FF FF FF FF FF FF FF FF FF FF FF FF
					39 00 00 40 00 00 02 6F 73
					39 00 00 40 00 00 15 C1 0D 4F DD 4F 4F DD 4F 4F DD 4F 4F DD 4F 4F BD 4F AC BB AC 9E
					39 00 00 40 00 00 2D BA 00 01 00 8A 00 8A 01 1E 01 1E 01 9D 01 9D 02 44 02 44 03 25 03 25 04 02 04 02 04 13 04 13 06 98 06 98 0A E2 0A E2 0D BB 0D BB 0F FE
					39 00 00 40 00 00 02 6F 07
					39 00 00 40 00 00 02 51 00
					39 00 00 40 00 00 05 FF AA 55 A5 80
					// Power on/off sequence related
					39 00 00 40 00 00 02 6F 08
					39 00 00 40 00 00 02 F6 54
					39 00 00 40 00 00 02 6F 0A
					39 00 00 40 00 00 07 F6 70 70 70 70 70 70
					// DMR flashing optimization
					39 00 00 40 00 00 05 FF AA 55 A5 81
					39 00 00 40 00 00 02 6F 0D
					39 00 00 40 00 00 02 FD 40
					// Charge Pump from 2uA to 4uA
					39 00 00 40 00 00 05 FF AA 55 A5 80
					39 00 00 40 00 00 02 6F 07
					39 00 00 40 00 00 02 F8 4D
					39 00 00 40 00 00 02 6F 23
					39 00 00 40 00 00 02 F8 4D
					// TE ON
					39 00 00 40 00 00 02 35 00
					//TE1F ON
					39 00 00 40 00 00 02 6F 15
					39 00 00 40 00 00 02 35 60
					39 00 00 40 00 00 02 6F 26
					39 00 00 40 00 00 08 44 00 00 00 00 08 07 60
					// BC Dimming OFF
					39 00 00 40 00 00 02 53 20
					// Normal DBV setting
					39 00 00 40 00 00 03 51 00 00
					// Idle DBV Setting
					39 00 00 40 00 00 02 6F 04
					39 00 00 40 00 00 03 51 0D DA
					// H_res = 1272  V_res = 2772
					39 00 00 40 00 00 05 2A 00 00 04 F7
					39 00 00 40 00 00 05 2B 00 00 0A D3
					// Compression method selection 10_8 2dsc & slice high 12 & vesa 1.2
					39 00 00 40 00 00 02 90 03
					39 00 00 40 00 00 02 6F 01
					39 00 00 40 00 00 02 90 43
					39 00 00 40 00 00 13 91 AB A8 00 0C C2 00 02 3E 01 37 00 08 08 BB 07 32 10 F0
					// GPIO Setting
					39 00 00 40 00 00 06 F0 55 AA 52 08 00
					39 00 00 40 00 00 05 BE 5F 4C 47 49
					// Round curve control
					39 00 00 40 00 00 06 F0 55 AA 52 08 07
					39 00 00 40 00 00 0E B8 01 00 F5 09 C8 00 00 00 00 00 00 00 00
					39 00 00 40 00 00 04 C0 A7 01 09
					39 00 00 40 00 00 02 6F 03
					39 00 00 40 00 00 05 C0 00 00 00 00
					39 00 00 40 00 00 16 C1 B0 0F 00 24 09 00 FD C0 3F FF DD B0 3F FE 6D 28 00 00 08 2D 10
					39 00 00 40 00 00 02 6F 15
					39 00 00 40 00 00 11 C1 06 01 94 0E 00 00 06 33 F0 FA 86 02 DC 00 00 00
					39 00 00 40 00 00 02 6F 25
					39 00 00 40 00 00 08 C1 00 00 05 00 8A 98 00
					39 00 00 40 00 00 16 C2 B0 0F 26 49 29 71 B0 56 3F C1 8B B2 3F C0 4D 0A 00 17 08 B0 2C
					39 00 00 40 00 00 02 6F 15
					39 00 00 40 00 00 11 C2 3D 00 06 93 00 05 97 43 F0 6F 73 4F DD C0 00 FF
					39 00 00 40 00 00 02 6F 25
					39 00 00 40 00 00 08 C2 00 90 93 00 00 05 00
					39 00 00 40 00 00 16 C3 B8 0F 05 A4 00 10 FE D0 3F FF 44 E0 3F FF F0 28 00 00 03 97 B0
					39 00 00 40 00 00 02 6F 15
					39 00 00 40 00 00 11 C3 5A 00 00 06 00 98 F2 33 F0 A6 FA 02 1C 00 00 00
					39 00 00 40 00 00 02 6F 25
					39 00 00 40 00 00 08 C3 44 64 67 00 00 05 00
					39 00 00 40 00 00 16 C4 BC 00 13 24 00 40 04 60 3F FB 1E 00 00 00 00 00 00 00 00 00 00
					39 00 00 40 00 00 02 6F 15
					39 00 00 40 00 00 11 C4 82 00 00 08 9A CB 4D 33 C0 7E 08 00 00 00 00 00
					39 00 00 40 00 00 02 6F 25
					39 00 00 40 00 00 08 C4 44 F2 F7 00 91 97 00
					39 00 00 40 00 00 16 C5 BC 00 17 C4 1A E9 32 94 3F BD 81 A4 00 10 C8 E8 00 00 00 00 00
					39 00 00 40 00 00 02 6F 15
					39 00 00 40 00 00 11 C5 50 00 08 8F AA 4E CE 33 C0 80 87 00 00 00 00 00
					39 00 00 40 00 00 02 6F 25
					39 00 00 40 00 00 08 C5 00 01 07 AA 4D 57 00
					39 00 00 40 00 00 16 C6 B4 00 00 01 01 B9 00 2A 3F FF FC 58 00 00 12 48 00 00 00 00 00
					39 00 00 40 00 00 02 6F 15
					39 00 00 40 00 00 11 C6 05 00 90 C3 AA CE D3 33 C0 FB 33 00 00 00 00 00
					39 00 00 40 00 00 02 6F 25
					39 00 00 40 00 00 08 C6 00 88 90 AA CF D3 00
					39 00 00 40 00 00 16 C7 31 00 05 A4 05 A4 00 00 3F FE 53 50 3F FE 53 50 00 00 1F D1 10
					39 00 00 40 00 00 02 6F 15
					39 00 00 40 00 00 11 C7 0B 22 55 7B 00 2C 52 33 F0 DA DA 05 A4 00 00 00
					39 00 00 40 00 00 02 6F 25
					39 00 00 40 00 00 08 C7 44 F0 F7 AA 4D 54 00
					39 00 00 40 00 00 16 C8 3D 00 05 A4 05 A4 00 00 3F FE 53 50 00 00 00 00 00 00 00 00 00
					39 00 00 40 00 00 02 6F 15
					39 00 00 40 00 00 11 C8 1A 22 55 7B 00 53 79 33 C0 DA 26 00 00 00 00 00
					39 00 00 40 00 00 02 6F 25
					39 00 00 40 00 00 08 C8 44 69 70 AA CF D3 00
					39 00 00 40 00 00 16 C9 27 00 05 A4 05 A4 00 00 00 00 00 00 3F FE 53 50 00 00 00 00 00
					39 00 00 40 00 00 02 6F 15
					39 00 00 40 00 00 11 C9 0B 22 7C A2 00 2C 52 33 30 26 DA 00 00 00 00 00
					39 00 00 40 00 00 02 6F 25
					39 00 00 40 00 00 08 C9 00 00 00 00 00 00 00
					39 00 00 40 00 00 16 CA 2B 00 05 A4 05 A4 00 00 00 00 00 00 00 00 00 00 7F FF E0 2E F0
					39 00 00 40 00 00 02 6F 15
					39 00 00 40 00 00 11 CA 1A 22 7C A2 00 53 79 33 0F 26 26 FA 5C 00 00 00
					39 00 00 40 00 00 02 6F 25
					39 00 00 40 00 00 08 CA 00 00 00 00 00 00 00
					39 00 00 40 00 00 16 CB 00 00 00 00 00 00 00 00 00 00 00 00 00 00 00 00 00 00 00 00 00
					39 00 00 40 00 00 02 6F 15
					39 00 00 40 00 00 11 CB 00 00 00 00 00 00 00 00 00 00 00 00 00 00 00 00
					39 00 00 40 00 00 02 6F 25
					39 00 00 40 00 00 08 CB 00 00 00 00 00 00 00
					39 00 00 40 00 00 16 CC 00 00 00 00 00 00 00 00 00 00 00 00 00 00 00 00 00 00 00 00 00
					39 00 00 40 00 00 02 6F 15
					39 00 00 40 00 00 11 CC 00 00 00 00 00 00 00 00 00 00 00 00 00 00 00 00
					39 00 00 40 00 00 02 6F 25
					39 00 00 40 00 00 08 CC 00 00 00 00 00 00 00
					39 00 00 40 00 00 16 CD 00 00 00 00 00 00 00 00 00 00 00 00 00 00 00 00 00 00 00 00 00
					39 00 00 40 00 00 02 6F 15
					39 00 00 40 00 00 11 CD 00 00 00 00 00 00 00 00 00 00 00 00 00 00 00 00
					39 00 00 40 00 00 02 6F 25
					39 00 00 40 00 00 08 CD 00 00 00 00 00 00 00
					39 00 00 40 00 00 16 CE 00 00 00 00 00 00 00 00 00 00 00 00 00 00 00 00 00 00 00 00 00
					39 00 00 40 00 00 02 6F 15
					39 00 00 40 00 00 11 CE 00 00 00 00 00 00 00 00 00 00 00 00 00 00 00 00
					39 00 00 40 00 00 02 6F 25
					39 00 00 40 00 00 08 CE 00 00 00 00 00 00 00
					39 00 00 40 00 00 16 CF 00 00 00 00 00 00 00 00 00 00 00 00 00 00 00 00 00 00 00 00 00
					39 00 00 40 00 00 02 6F 15
					39 00 00 40 00 00 11 CF 00 00 00 00 00 00 00 00 00 00 00 00 00 00 00 00
					39 00 00 40 00 00 02 6F 25
					39 00 00 40 00 00 08 CF 00 00 00 00 00 00 00
					39 00 00 40 00 00 16 D0 00 00 00 00 00 00 00 00 00 00 00 00 00 00 00 00 00 00 00 00 00
					39 00 00 40 00 00 02 6F 15
					39 00 00 40 00 00 11 D0 00 00 00 00 00 00 00 00 00 00 00 00 00 00 00 00
					39 00 00 40 00 00 02 6F 25
					39 00 00 40 00 00 08 D0 00 00 00 00 00 00 00
					39 00 00 40 00 00 0F D1 80 00 00 00 00 04 F8 80 00 6B BD 09 04 F7
					39 00 00 40 00 00 02 6F 0E
					39 00 00 40 00 00 0F D1 80 00 00 00 00 04 F7 FF FF DD B9 00 04 F7
					39 00 00 40 00 00 02 6F 1C
					39 00 00 40 00 00 0F D1 FF E3 8B 46 00 04 F7 FF FF FF 4F B1 04 F8
					39 00 00 40 00 00 02 6F 2A
					39 00 00 40 00 00 0C D1 00 00 00 00 00 04 F8 7F FF E0 2E
					39 00 00 40 00 00 12 D2 F0 04 F8 00 00 1F D1 10 04 F8 00 00 00 00 00 04 F8
					//RCN
					39 00 00 40 00 00 06 F0 55 AA 52 08 07
					39 00 00 40 00 00 02 C0 A7
					//OSC trim
					39 00 00 40 00 00 06 F0 55 AA 52 08 01
					39 00 00 40 00 00 36 C3 99 29 02 6B 19 00 29 00 6B 19 00 3F 5A 08 3F 1A D4 3F 2A 07 3F 28 D4 3F 25 06 3F 61 D4 3F 3B 46 3F 46 07 3F 5A 08 3F 1A D4 11 11 01 00 10 00 77 00 AA 02 AA 02
					39 00 00 40 00 00 06 F0 55 AA 52 08 01
					39 00 00 40 00 00 07 B3 44 44 44 44 44 44
					39 00 00 40 00 00 06 F0 55 AA 52 08 07
					39 00 00 40 00 00 0E B4 C0 50 60 60 50 35 80 20 60 58 80 38 70
					//OD
					39 00 00 40 00 00 06 F0 55 AA 52 08 08
					39 00 00 40 00 00 05 E0 01 01 81 01
					39 00 00 40 00 00 02 6F 06
					39 00 00 40 00 00 0E E0 80 00 21 32 43 54 65 66 66 76 87 98 99
					39 00 00 40 00 00 06 F0 55 AA 52 08 08
					39 00 00 40 00 00 02 6F 04
					39 00 00 40 00 00 02 E0 20
					39 00 00 40 00 00 02 6F 1B
					39 00 00 40 00 00 04 EB 44 00 00
					39 00 00 40 00 00 02 6F 1E
					39 00 00 40 00 00 04 EB 94 00 00
					39 00 00 40 00 00 02 6F 21
					39 00 00 40 00 00 03 EB 04 00
					39 00 00 40 00 00 02 6F 24
					39 00 00 40 00 00 04 EB 10 32 54
					39 00 00 40 00 00 0F E1 03 04 20 00 00 00 00 00 00 00 00 00 00 00
					39 00 00 40 00 00 0F E2 03 04 20 00 00 00 00 00 00 00 00 00 00 00
					39 00 00 40 00 00 0F E3 00 00 00 00 00 00 00 00 00 00 00 00 00 00
					39 00 00 40 00 00 02 6F 0E
					39 00 00 40 00 00 0F E1 02 04 24 03 03 03 03 03 03 03 03 08 0F 1A
					39 00 00 40 00 00 02 6F 0E
					39 00 00 40 00 00 0F E2 03 04 24 03 03 03 03 03 03 03 03 09 0E 17
					39 00 00 40 00 00 02 6F 0E
					39 00 00 40 00 00 0F E3 03 04 06 03 03 03 03 03 03 04 03 09 0E 07
					39 00 00 40 00 00 02 6F 1C
					39 00 00 40 00 00 0F E1 01 03 1D 03 03 03 03 03 03 03 03 03 08 0F
					39 00 00 40 00 00 02 6F 1C
					39 00 00 40 00 00 0F E2 02 03 1D 04 04 04 04 04 04 04 04 04 07 0C
					39 00 00 40 00 00 02 6F 1C
					39 00 00 40 00 00 0F E3 02 03 05 04 04 04 04 04 04 04 04 03 07 12
					39 00 00 40 00 00 02 6F 2A
					39 00 00 40 00 00 0F E1 01 03 18 04 04 04 04 04 04 04 04 04 07 0E
					39 00 00 40 00 00 02 6F 2A
					39 00 00 40 00 00 0F E2 02 03 18 03 03 03 03 03 03 03 03 03 06 0D
					39 00 00 40 00 00 02 6F 2A
					39 00 00 40 00 00 0F E3 01 01 04 03 03 03 03 03 03 03 03 05 0B 13
					39 00 00 40 00 00 02 6F 38
					39 00 00 40 00 00 0F E1 02 04 10 04 04 04 04 04 04 04 04 09 10 1A
					39 00 00 40 00 00 02 6F 38
					39 00 00 40 00 00 0F E2 03 04 10 04 04 04 04 04 04 04 04 05 09 11
					39 00 00 40 00 00 02 6F 38
					39 00 00 40 00 00 0F E3 01 01 04 04 04 04 04 04 04 04 05 05 0A 13
					39 00 00 40 00 00 02 6F 46
					39 00 00 40 00 00 0F E1 02 04 08 03 03 03 03 03 05 05 05 05 05 10
					39 00 00 40 00 00 02 6F 46
					39 00 00 40 00 00 0F E2 03 04 08 03 03 03 03 03 04 04 04 04 04 06
					39 00 00 40 00 00 02 6F 46
					39 00 00 40 00 00 0F E3 01 01 04 03 03 03 03 03 04 04 04 04 04 06
					39 00 00 40 00 00 02 6F 54
					39 00 00 40 00 00 0F E1 01 02 03 04 05 05 05 03 03 03 02 02 02 02
					39 00 00 40 00 00 02 6F 54
					39 00 00 40 00 00 0F E2 01 02 04 04 04 05 05 02 02 01 01 01 01 01
					39 00 00 40 00 00 02 6F 54
					39 00 00 40 00 00 0F E3 00 01 02 02 04 05 05 02 02 01 01 01 01 01
					39 00 00 40 00 00 02 6F 62
					39 00 00 40 00 00 0F E1 01 02 03 04 04 04 04 03 03 03 02 02 02 02
					39 00 00 40 00 00 02 6F 62
					39 00 00 40 00 00 0F E2 01 02 03 03 03 03 03 02 02 01 01 01 01 01
					39 00 00 40 00 00 02 6F 62
					39 00 00 40 00 00 0F E3 01 02 03 03 03 03 03 02 02 01 01 01 01 01
					39 00 00 40 00 00 02 6F 70
					39 00 00 40 00 00 0F E1 01 02 03 04 04 04 04 03 03 03 02 02 02 02
					39 00 00 40 00 00 02 6F 70
					39 00 00 40 00 00 0F E2 01 02 03 04 05 04 04 02 02 02 01 01 01 01
					39 00 00 40 00 00 02 6F 70
					39 00 00 40 00 00 0F E3 01 02 03 04 05 04 04 02 02 02 01 01 01 01
					15 00 00 00 78 00 02 11 00
					// Display on
					15 00 00 00 00 00 02 29 00
					39 00 00 40 00 00 02 68 00
					39 00 00 40 00 00 06 F0 55 AA 52 08 00
					39 00 00 40 00 00 02 6F 04
					39 00 00 40 00 00 02 B1 00
					39 00 00 40 00 00 02 6F 2A
					39 00 00 40 00 00 02 BB 00
					39 00 00 40 00 00 02 6F 30
					39 00 00 40 00 00 02 C0 3F
					39 00 00 40 00 00 06 F0 55 AA 52 08 09
					39 00 00 40 00 00 02 BD 04
					39 00 00 40 00 00 02 6F 01
					39 00 00 40 00 00 0A BD 31 9D 25 54 13 14 A6 98 E2
					39 00 00 40 00 00 02 6F 0A
					39 00 00 40 00 00 06 BD 10 20 40 80 FF
					39 00 00 40 00 00 02 6F 1A
					39 00 00 40 00 00 06 BD FF FF FF FF FF
					39 00 00 40 00 00 02 6F 10
					39 00 00 40 00 00 04 BD FD 07 00
					39 00 00 40 00 00 02 6F 16
					39 00 00 40 00 00 02 BD 15
					39 00 00 40 00 00 06 F0 55 AA 52 08 09
					39 00 00 40 00 00 02 6F 00
					39 00 00 40 00 00 1F BE 19 14 0A 23 1E 05 05 00 05 0A 01 01 03 06 82 00 02 02 00 09 81 02 80 88 0B 01 00 00 07 81
					39 00 00 40 00 00 02 6F 1E
					39 00 00 40 00 00 1F BE 19 14 0A 23 1E 05 05 00 05 0A 01 01 03 06 82 00 02 02 00 09 81 02 80 88 0B 01 00 00 07 81
					39 00 00 40 00 00 02 6F 3C
					39 00 00 40 00 00 1F BE 19 14 0A 23 1E 05 05 00 05 0A 01 01 03 06 82 00 02 02 00 09 81 02 80 88 0B 01 00 00 07 81
					39 00 00 40 00 00 06 F0 55 AA 52 08 09
					39 00 00 40 00 00 02 6F 00
					39 00 00 40 00 00 1F BF 19 18 0C 18 2C 08 02 02 0A 04 04 04 10 08 14 01 04 06 00 0C 00 00 04 89 88 02 02 05 02 0A
					39 00 00 40 00 00 02 6F 1E
					39 00 00 40 00 00 1F BF 19 18 0C 18 2C 08 02 02 0A 04 04 04 10 08 14 01 04 06 00 0C 00 00 04 89 88 02 02 05 02 0A
					39 00 00 40 00 00 02 6F 3C
					39 00 00 40 00 00 1F BF 19 18 0C 18 2C 08 02 02 0A 04 04 04 10 08 14 01 04 06 00 0C 00 00 04 89 88 02 02 05 02 0A
					// 90Hz Freq. Setting
					39 00 00 40 00 00 2D A9 01 00 44 26 27 00 00 01 00 44 28 2C 00 00 08 07 60 02 01 C3 23 25 3F 2A 07 02 01 C3 26 27 3F 28 02 01 C3 28 28 D4 02 01 C3 2E 2E 00
					39 00 00 40 00 00 B5 A9 02 08 E0 00 00 00 02 08 E1 02 02 20 02 08 E2 02 02 20 02 08 E1 10 10 24 02 08 E2 10 10 24 02 08 E1 1E 1E 1D 02 08 E2 1E 1E 1D 02 08 E1 2C 2C 18 02 08 E2 2C 2C 18 02 08 E1 3A 3A 10 02 08 E2 3A 3A 10 02 08 E3 3A 3A 04 02 08 E1 43 45 09 10 1A 02 08 E2 43 45 05 09 11 02 08 E3 43 45 05 0A 13 02 08 E1 48 48 08 02 08 E2 48 48 08 02 08 E3 48 48 04 02 08 E1 55 56 02 03 02 08 E2 56 56 04 02 08 E3 55 56 01 02 02 08 E1 64 64 03 02 08 E2 64 64 03 02 08 E3 62 64 01 02 03 02 08 E1 72 72 03 02 08 E2 72 72 03 02 08 E3 70 72 01 02 03 02 08 E0 00 00 01
					39 00 00 00 00 00 91 A9 01 00 68 00 00 00 02 01 DD 02 03 00 00 02 04 B5 01 03 00 00 03 01 00 9D 00 00 AA 02 08 B0 00 00 00 01 00 A2 00 47 13 02 09 BD 00 00 04 00 00 00 00 00 00 00 02 08 B7 20 27 08 00 08 00 07 B3 07 B3 02 08 B7 28 2D 07 CC 07 CC 08 00 00 00 02 08 B0 00 00 00 00 00 00 00 00 00 00 01 00 2F 00 00 01 00 00 00 00 00 00 00 02 01 B9 1D 1D 4A 01 00 8D 02 02 01 01 00 A3 00 0F 82 00 00 00 00 02 01 B9 1D 1D 4A 00 00 00 00 00 01 00 A3 10 11 00 00
				];

			};
			timing@sdc_fhd_60 {
				#include "dsi-panel-AE106-P-1-A0037-common.dtsi"
				#include "dsi-panel-AE106-P-1-A0037-common-effect.dtsi"
				qcom,mdss-mdp-transfer-time-us = <6900>;
				qcom,mdss-dsi-timing-default;
				qcom,mdss-dsi-panel-framerate = <60>;
				qcom,mdss-dsi-panel-clockrate = <1153600000>;
				qcom,mdss-dsi-panel-width = <1272>;
				qcom,mdss-dsi-panel-height = <2772>;
				oplus,apollo-panel-async-bl-delay = <9000>;

				qcom,mdss-dsi-h-front-porch = <16>;
				qcom,mdss-dsi-h-back-porch = <16>;
				qcom,mdss-dsi-h-pulse-width = <2>;
				qcom,mdss-dsi-v-back-porch = <28>;
				qcom,mdss-dsi-v-front-porch = <78>;
				qcom,mdss-dsi-v-pulse-width = <2>;
				qcom,mdss-dsi-h-sync-pulse = <0>;

				oplus,ofp-need-to-sync-data-in-aod-unlocking;
				oplus,ofp-aod-off-insert-black-frame = <1>;
				oplus,ofp-aod-off-black-frame-total-time = <42>;
				oplus,ofp-need-to-separate-backlight;
				oplus,ofp-backlight-on-period = <1>;

				qcom,mdss-dsi-timing-switch-command = [
					39 00 00 40 00 00 2D A9 01 00 44 26 27 00 00 01 00 44 28 2C 00 00 05 0A FF 02 01 C3 23 25 3F 5A 08 02 01 C3 26 27 3F 1A 02 01 C3 28 28 D4 02 01 C3 2E 2E 00
					39 00 00 40 00 00 B5 A9 02 08 E0 00 00 00 02 08 E1 02 02 20 02 08 E2 02 02 20 02 08 E1 10 10 24 02 08 E2 10 10 24 02 08 E1 1E 1E 1D 02 08 E2 1E 1E 1D 02 08 E1 2C 2C 18 02 08 E2 2C 2C 18 02 08 E1 3A 3A 10 02 08 E2 3A 3A 10 02 08 E3 3A 3A 04 02 08 E1 43 45 09 10 1A 02 08 E2 43 45 05 09 11 02 08 E3 43 45 05 0A 13 02 08 E1 48 48 08 02 08 E2 48 48 08 02 08 E3 48 48 04 02 08 E1 55 56 02 03 02 08 E2 56 56 04 02 08 E3 55 56 01 02 02 08 E1 64 64 03 02 08 E2 64 64 03 02 08 E3 62 64 01 02 03 02 08 E1 72 72 03 02 08 E2 72 72 03 02 08 E3 70 72 01 02 03 02 08 E0 00 00 01
					39 00 00 00 00 00 91 A9 01 00 68 00 00 00 02 01 DD 02 03 00 00 02 04 B5 01 03 00 00 09 01 00 9D 00 00 AA 02 08 B0 00 00 00 01 00 A2 00 47 13 02 09 BD 00 00 04 00 00 00 00 00 00 00 02 08 B7 20 27 08 00 08 00 07 B3 07 B3 02 08 B7 28 2D 07 CC 07 CC 08 00 00 00 02 08 B0 00 00 00 00 00 00 00 00 00 00 01 00 2F 00 00 04 00 00 00 00 00 00 00 02 01 B9 20 20 4A 01 00 8D 02 02 01 01 00 A3 00 0F 82 00 00 00 00 02 01 B9 20 20 4A 00 00 00 00 00 01 00 A3 10 11 00 00
				];
				qcom,mdss-dsi-on-command = [
					// Flash lock and reload
					39 00 00 40 00 00 06 F0 55 AA 52 08 04
					39 00 00 40 00 00 02 6F 03
					39 00 00 40 00 00 02 B5 0B
					39 00 00 40 00 00 02 C0 20
					39 00 00 40 00 00 02 C1 1C
					39 00 00 40 00 00 02 C0 80
					// DMR LUT SET
					39 00 00 40 00 00 02 C0 40
					39 00 00 40 00 00 06 F0 55 AA 52 08 00
					39 00 00 40 00 00 02 6F 31
					39 00 00 40 00 00 04 C0 01 02 10
					39 00 00 40 00 00 02 6F 08
					39 00 00 40 00 00 04 C7 98 97 80
					// APL BLK setting
					39 00 00 40 00 00 06 F0 55 AA 52 08 00
					39 00 00 40 00 00 02 6F 78
					39 00 00 40 00 00 18 B0 11 00 2A 00 C2 01 DA 03 7C 05 B1 08 80 0B EE 0F FF 05 55 05 56 05 55
					39 00 00 40 00 00 02 6F 6F
					39 00 00 40 00 00 07 B0 02 7C 04 F8 02 7C
					39 00 00 40 00 00 06 F0 55 AA 52 08 08
					39 00 00 40 00 00 17 C1 9D 4F DD 4F 4F DD 4F 4F DD 4F 4F DD 4F 4F BD 4F AC BB AC 9E 0D FF
					39 00 00 40 00 00 02 6F 1D
					39 00 00 40 00 00 04 C1 00 FF FF
					39 00 00 40 00 00 02 6F 20
					39 00 00 40 00 00 04 C1 3F 33 FF
					39 00 00 40 00 00 02 6F 23
					39 00 00 40 00 00 15 C1 0D 4F DD 4F 4F DD 4F 4F DD 4F 4F DD 4F 4F BD 4F AC BB AC 9E
					39 00 00 40 00 00 02 6F 37
					39 00 00 40 00 00 15 C1 0E FF EE FF FF EE FF FF EE FF FF EE FF FF DE FF 27 DD 27 27
					39 00 00 40 00 00 02 6F 4B
					39 00 00 40 00 00 15 C1 0D 4F DD 4F 4F DD 4F 4F DD 4F 4F DD 4F 4F BD 4F AC BB AC 9E
					39 00 00 40 00 00 02 6F 5F
					39 00 00 40 00 00 15 C1 0F FF FF FF FF FF FF FF FF FF FF FF FF FF FF FF FF FF FF FF
					39 00 00 40 00 00 02 6F 73
					39 00 00 40 00 00 15 C1 0D 4F DD 4F 4F DD 4F 4F DD 4F 4F DD 4F 4F BD 4F AC BB AC 9E
					39 00 00 40 00 00 2D BA 00 01 00 8A 00 8A 01 1E 01 1E 01 9D 01 9D 02 44 02 44 03 25 03 25 04 02 04 02 04 13 04 13 06 98 06 98 0A E2 0A E2 0D BB 0D BB 0F FE
					39 00 00 40 00 00 02 6F 07
					39 00 00 40 00 00 02 51 00
					39 00 00 40 00 00 05 FF AA 55 A5 80
					// Power on/off sequence related
					39 00 00 40 00 00 02 6F 08
					39 00 00 40 00 00 02 F6 54
					39 00 00 40 00 00 02 6F 0A
					39 00 00 40 00 00 07 F6 70 70 70 70 70 70
					// DMR flashing optimization
					39 00 00 40 00 00 05 FF AA 55 A5 81
					39 00 00 40 00 00 02 6F 0D
					39 00 00 40 00 00 02 FD 40
					// Charge Pump from 2uA to 4uA
					39 00 00 40 00 00 05 FF AA 55 A5 80
					39 00 00 40 00 00 02 6F 07
					39 00 00 40 00 00 02 F8 4D
					39 00 00 40 00 00 02 6F 23
					39 00 00 40 00 00 02 F8 4D
					// TE ON
					39 00 00 40 00 00 02 35 00
					//TE1F ON
					39 00 00 40 00 00 02 6F 15
					39 00 00 40 00 00 02 35 60
					39 00 00 40 00 00 02 6F 26
					39 00 00 40 00 00 08 44 00 00 00 00 05 0A FF
					// BC Dimming OFF
					39 00 00 40 00 00 02 53 20
					// Normal DBV setting
					39 00 00 40 00 00 03 51 00 00
					// Idle DBV Setting
					39 00 00 40 00 00 02 6F 04
					39 00 00 40 00 00 03 51 0D DA
					// H_res = 1272  V_res = 2772
					39 00 00 40 00 00 05 2A 00 00 04 F7
					39 00 00 40 00 00 05 2B 00 00 0A D3
					// Compression method selection 10_8 2dsc & slice high 12 & vesa 1.2
					39 00 00 40 00 00 02 90 03
					39 00 00 40 00 00 02 6F 01
					39 00 00 40 00 00 02 90 43
					39 00 00 40 00 00 13 91 AB A8 00 0C C2 00 02 3E 01 37 00 08 08 BB 07 32 10 F0
					// GPIO Setting
					39 00 00 40 00 00 06 F0 55 AA 52 08 00
					39 00 00 40 00 00 05 BE 5F 4C 47 49
					// Round curve control
					39 00 00 40 00 00 06 F0 55 AA 52 08 07
					39 00 00 40 00 00 0E B8 01 00 F5 09 C8 00 00 00 00 00 00 00 00
					39 00 00 40 00 00 04 C0 A7 01 09
					39 00 00 40 00 00 02 6F 03
					39 00 00 40 00 00 05 C0 00 00 00 00
					39 00 00 40 00 00 16 C1 B0 0F 00 24 09 00 FD C0 3F FF DD B0 3F FE 6D 28 00 00 08 2D 10
					39 00 00 40 00 00 02 6F 15
					39 00 00 40 00 00 11 C1 06 01 94 0E 00 00 06 33 F0 FA 86 02 DC 00 00 00
					39 00 00 40 00 00 02 6F 25
					39 00 00 40 00 00 08 C1 00 00 05 00 8A 98 00
					39 00 00 40 00 00 16 C2 B0 0F 26 49 29 71 B0 56 3F C1 8B B2 3F C0 4D 0A 00 17 08 B0 2C
					39 00 00 40 00 00 02 6F 15
					39 00 00 40 00 00 11 C2 3D 00 06 93 00 05 97 43 F0 6F 73 4F DD C0 00 FF
					39 00 00 40 00 00 02 6F 25
					39 00 00 40 00 00 08 C2 00 90 93 00 00 05 00
					39 00 00 40 00 00 16 C3 B8 0F 05 A4 00 10 FE D0 3F FF 44 E0 3F FF F0 28 00 00 03 97 B0
					39 00 00 40 00 00 02 6F 15
					39 00 00 40 00 00 11 C3 5A 00 00 06 00 98 F2 33 F0 A6 FA 02 1C 00 00 00
					39 00 00 40 00 00 02 6F 25
					39 00 00 40 00 00 08 C3 44 64 67 00 00 05 00
					39 00 00 40 00 00 16 C4 BC 00 13 24 00 40 04 60 3F FB 1E 00 00 00 00 00 00 00 00 00 00
					39 00 00 40 00 00 02 6F 15
					39 00 00 40 00 00 11 C4 82 00 00 08 9A CB 4D 33 C0 7E 08 00 00 00 00 00
					39 00 00 40 00 00 02 6F 25
					39 00 00 40 00 00 08 C4 44 F2 F7 00 91 97 00
					39 00 00 40 00 00 16 C5 BC 00 17 C4 1A E9 32 94 3F BD 81 A4 00 10 C8 E8 00 00 00 00 00
					39 00 00 40 00 00 02 6F 15
					39 00 00 40 00 00 11 C5 50 00 08 8F AA 4E CE 33 C0 80 87 00 00 00 00 00
					39 00 00 40 00 00 02 6F 25
					39 00 00 40 00 00 08 C5 00 01 07 AA 4D 57 00
					39 00 00 40 00 00 16 C6 B4 00 00 01 01 B9 00 2A 3F FF FC 58 00 00 12 48 00 00 00 00 00
					39 00 00 40 00 00 02 6F 15
					39 00 00 40 00 00 11 C6 05 00 90 C3 AA CE D3 33 C0 FB 33 00 00 00 00 00
					39 00 00 40 00 00 02 6F 25
					39 00 00 40 00 00 08 C6 00 88 90 AA CF D3 00
					39 00 00 40 00 00 16 C7 31 00 05 A4 05 A4 00 00 3F FE 53 50 3F FE 53 50 00 00 1F D1 10
					39 00 00 40 00 00 02 6F 15
					39 00 00 40 00 00 11 C7 0B 22 55 7B 00 2C 52 33 F0 DA DA 05 A4 00 00 00
					39 00 00 40 00 00 02 6F 25
					39 00 00 40 00 00 08 C7 44 F0 F7 AA 4D 54 00
					39 00 00 40 00 00 16 C8 3D 00 05 A4 05 A4 00 00 3F FE 53 50 00 00 00 00 00 00 00 00 00
					39 00 00 40 00 00 02 6F 15
					39 00 00 40 00 00 11 C8 1A 22 55 7B 00 53 79 33 C0 DA 26 00 00 00 00 00
					39 00 00 40 00 00 02 6F 25
					39 00 00 40 00 00 08 C8 44 69 70 AA CF D3 00
					39 00 00 40 00 00 16 C9 27 00 05 A4 05 A4 00 00 00 00 00 00 3F FE 53 50 00 00 00 00 00
					39 00 00 40 00 00 02 6F 15
					39 00 00 40 00 00 11 C9 0B 22 7C A2 00 2C 52 33 30 26 DA 00 00 00 00 00
					39 00 00 40 00 00 02 6F 25
					39 00 00 40 00 00 08 C9 00 00 00 00 00 00 00
					39 00 00 40 00 00 16 CA 2B 00 05 A4 05 A4 00 00 00 00 00 00 00 00 00 00 7F FF E0 2E F0
					39 00 00 40 00 00 02 6F 15
					39 00 00 40 00 00 11 CA 1A 22 7C A2 00 53 79 33 0F 26 26 FA 5C 00 00 00
					39 00 00 40 00 00 02 6F 25
					39 00 00 40 00 00 08 CA 00 00 00 00 00 00 00
					39 00 00 40 00 00 16 CB 00 00 00 00 00 00 00 00 00 00 00 00 00 00 00 00 00 00 00 00 00
					39 00 00 40 00 00 02 6F 15
					39 00 00 40 00 00 11 CB 00 00 00 00 00 00 00 00 00 00 00 00 00 00 00 00
					39 00 00 40 00 00 02 6F 25
					39 00 00 40 00 00 08 CB 00 00 00 00 00 00 00
					39 00 00 40 00 00 16 CC 00 00 00 00 00 00 00 00 00 00 00 00 00 00 00 00 00 00 00 00 00
					39 00 00 40 00 00 02 6F 15
					39 00 00 40 00 00 11 CC 00 00 00 00 00 00 00 00 00 00 00 00 00 00 00 00
					39 00 00 40 00 00 02 6F 25
					39 00 00 40 00 00 08 CC 00 00 00 00 00 00 00
					39 00 00 40 00 00 16 CD 00 00 00 00 00 00 00 00 00 00 00 00 00 00 00 00 00 00 00 00 00
					39 00 00 40 00 00 02 6F 15
					39 00 00 40 00 00 11 CD 00 00 00 00 00 00 00 00 00 00 00 00 00 00 00 00
					39 00 00 40 00 00 02 6F 25
					39 00 00 40 00 00 08 CD 00 00 00 00 00 00 00
					39 00 00 40 00 00 16 CE 00 00 00 00 00 00 00 00 00 00 00 00 00 00 00 00 00 00 00 00 00
					39 00 00 40 00 00 02 6F 15
					39 00 00 40 00 00 11 CE 00 00 00 00 00 00 00 00 00 00 00 00 00 00 00 00
					39 00 00 40 00 00 02 6F 25
					39 00 00 40 00 00 08 CE 00 00 00 00 00 00 00
					39 00 00 40 00 00 16 CF 00 00 00 00 00 00 00 00 00 00 00 00 00 00 00 00 00 00 00 00 00
					39 00 00 40 00 00 02 6F 15
					39 00 00 40 00 00 11 CF 00 00 00 00 00 00 00 00 00 00 00 00 00 00 00 00
					39 00 00 40 00 00 02 6F 25
					39 00 00 40 00 00 08 CF 00 00 00 00 00 00 00
					39 00 00 40 00 00 16 D0 00 00 00 00 00 00 00 00 00 00 00 00 00 00 00 00 00 00 00 00 00
					39 00 00 40 00 00 02 6F 15
					39 00 00 40 00 00 11 D0 00 00 00 00 00 00 00 00 00 00 00 00 00 00 00 00
					39 00 00 40 00 00 02 6F 25
					39 00 00 40 00 00 08 D0 00 00 00 00 00 00 00
					39 00 00 40 00 00 0F D1 80 00 00 00 00 04 F8 80 00 6B BD 09 04 F7
					39 00 00 40 00 00 02 6F 0E
					39 00 00 40 00 00 0F D1 80 00 00 00 00 04 F7 FF FF DD B9 00 04 F7
					39 00 00 40 00 00 02 6F 1C
					39 00 00 40 00 00 0F D1 FF E3 8B 46 00 04 F7 FF FF FF 4F B1 04 F8
					39 00 00 40 00 00 02 6F 2A
					39 00 00 40 00 00 0C D1 00 00 00 00 00 04 F8 7F FF E0 2E
					39 00 00 40 00 00 12 D2 F0 04 F8 00 00 1F D1 10 04 F8 00 00 00 00 00 04 F8
					//RCN
					39 00 00 40 00 00 06 F0 55 AA 52 08 07
					39 00 00 40 00 00 02 C0 A7
					//OSC trim
					39 00 00 40 00 00 06 F0 55 AA 52 08 01
					39 00 00 40 00 00 36 C3 99 29 02 6B 19 00 29 00 6B 19 00 3F 5A 08 3F 1A D4 3F 2A 07 3F 28 D4 3F 25 06 3F 61 D4 3F 3B 46 3F 46 07 3F 5A 08 3F 1A D4 11 11 01 00 10 00 77 00 AA 02 AA 02
					39 00 00 40 00 00 06 F0 55 AA 52 08 01
					39 00 00 40 00 00 07 B3 44 44 44 44 44 44
					39 00 00 40 00 00 06 F0 55 AA 52 08 07
					39 00 00 40 00 00 0E B4 C0 50 60 60 50 35 80 20 60 58 80 38 70
					//OD
					39 00 00 40 00 00 06 F0 55 AA 52 08 08
					39 00 00 40 00 00 05 E0 01 01 81 01
					39 00 00 40 00 00 02 6F 06
					39 00 00 40 00 00 0E E0 80 00 21 32 43 54 65 66 66 76 87 98 99
					39 00 00 40 00 00 06 F0 55 AA 52 08 08
					39 00 00 40 00 00 02 6F 04
					39 00 00 40 00 00 02 E0 20
					39 00 00 40 00 00 02 6F 1B
					39 00 00 40 00 00 04 EB 44 00 00
					39 00 00 40 00 00 02 6F 1E
					39 00 00 40 00 00 04 EB 94 00 00
					39 00 00 40 00 00 02 6F 21
					39 00 00 40 00 00 03 EB 04 00
					39 00 00 40 00 00 02 6F 24
					39 00 00 40 00 00 04 EB 10 32 54
					39 00 00 40 00 00 0F E1 03 04 20 00 00 00 00 00 00 00 00 00 00 00
					39 00 00 40 00 00 0F E2 03 04 20 00 00 00 00 00 00 00 00 00 00 00
					39 00 00 40 00 00 0F E3 00 00 00 00 00 00 00 00 00 00 00 00 00 00
					39 00 00 40 00 00 02 6F 0E
					39 00 00 40 00 00 0F E1 02 04 24 03 03 03 03 03 03 03 03 08 0F 1A
					39 00 00 40 00 00 02 6F 0E
					39 00 00 40 00 00 0F E2 03 04 24 03 03 03 03 03 03 03 03 09 0E 17
					39 00 00 40 00 00 02 6F 0E
					39 00 00 40 00 00 0F E3 03 04 06 03 03 03 03 03 03 04 03 09 0E 07
					39 00 00 40 00 00 02 6F 1C
					39 00 00 40 00 00 0F E1 01 03 1D 03 03 03 03 03 03 03 03 03 08 0F
					39 00 00 40 00 00 02 6F 1C
					39 00 00 40 00 00 0F E2 02 03 1D 04 04 04 04 04 04 04 04 04 07 0C
					39 00 00 40 00 00 02 6F 1C
					39 00 00 40 00 00 0F E3 02 03 05 04 04 04 04 04 04 04 04 03 07 12
					39 00 00 40 00 00 02 6F 2A
					39 00 00 40 00 00 0F E1 01 03 18 04 04 04 04 04 04 04 04 04 07 0E
					39 00 00 40 00 00 02 6F 2A
					39 00 00 40 00 00 0F E2 02 03 18 03 03 03 03 03 03 03 03 03 06 0D
					39 00 00 40 00 00 02 6F 2A
					39 00 00 40 00 00 0F E3 01 01 04 03 03 03 03 03 03 03 03 05 0B 13
					39 00 00 40 00 00 02 6F 38
					39 00 00 40 00 00 0F E1 02 04 10 04 04 04 04 04 04 04 04 09 10 1A
					39 00 00 40 00 00 02 6F 38
					39 00 00 40 00 00 0F E2 03 04 10 04 04 04 04 04 04 04 04 05 09 11
					39 00 00 40 00 00 02 6F 38
					39 00 00 40 00 00 0F E3 01 01 04 04 04 04 04 04 04 04 05 05 0A 13
					39 00 00 40 00 00 02 6F 46
					39 00 00 40 00 00 0F E1 02 04 08 03 03 03 03 03 05 05 05 05 05 10
					39 00 00 40 00 00 02 6F 46
					39 00 00 40 00 00 0F E2 03 04 08 03 03 03 03 03 04 04 04 04 04 06
					39 00 00 40 00 00 02 6F 46
					39 00 00 40 00 00 0F E3 01 01 04 03 03 03 03 03 04 04 04 04 04 06
					39 00 00 40 00 00 02 6F 54
					39 00 00 40 00 00 0F E1 01 02 03 04 05 05 05 03 03 03 02 02 02 02
					39 00 00 40 00 00 02 6F 54
					39 00 00 40 00 00 0F E2 01 02 04 04 04 05 05 02 02 01 01 01 01 01
					39 00 00 40 00 00 02 6F 54
					39 00 00 40 00 00 0F E3 00 01 02 02 04 05 05 02 02 01 01 01 01 01
					39 00 00 40 00 00 02 6F 62
					39 00 00 40 00 00 0F E1 01 02 03 04 04 04 04 03 03 03 02 02 02 02
					39 00 00 40 00 00 02 6F 62
					39 00 00 40 00 00 0F E2 01 02 03 03 03 03 03 02 02 01 01 01 01 01
					39 00 00 40 00 00 02 6F 62
					39 00 00 40 00 00 0F E3 01 02 03 03 03 03 03 02 02 01 01 01 01 01
					39 00 00 40 00 00 02 6F 70
					39 00 00 40 00 00 0F E1 01 02 03 04 04 04 04 03 03 03 02 02 02 02
					39 00 00 40 00 00 02 6F 70
					39 00 00 40 00 00 0F E2 01 02 03 04 05 04 04 02 02 02 01 01 01 01
					39 00 00 40 00 00 02 6F 70
					39 00 00 40 00 00 0F E3 01 02 03 04 05 04 04 02 02 02 01 01 01 01
					// Sleep out
					15 00 00 00 78 00 02 11 00
					// Display on
					15 00 00 00 00 00 02 29 00
					39 00 00 40 00 00 02 68 00
					39 00 00 40 00 00 06 F0 55 AA 52 08 00
					39 00 00 40 00 00 02 6F 04
					39 00 00 40 00 00 02 B1 00
					39 00 00 40 00 00 02 6F 2A
					39 00 00 40 00 00 02 BB 00
					39 00 00 40 00 00 02 6F 30
					39 00 00 40 00 00 02 C0 3F
					39 00 00 40 00 00 06 F0 55 AA 52 08 09
					39 00 00 40 00 00 02 BD 04
					39 00 00 40 00 00 02 6F 01
					39 00 00 40 00 00 0A BD 31 9D 25 54 13 14 A6 98 E2
					39 00 00 40 00 00 02 6F 0A
					39 00 00 40 00 00 06 BD 10 20 40 80 FF
					39 00 00 40 00 00 02 6F 1A
					39 00 00 40 00 00 06 BD FF FF FF FF FF
					39 00 00 40 00 00 02 6F 10
					39 00 00 40 00 00 04 BD FD 07 00
					39 00 00 40 00 00 02 6F 16
					39 00 00 40 00 00 02 BD 15
					39 00 00 40 00 00 06 F0 55 AA 52 08 09
					39 00 00 40 00 00 02 6F 00
					39 00 00 40 00 00 1F BE 19 14 0A 23 1E 05 05 00 05 0A 01 01 03 06 82 00 02 02 00 09 81 02 80 88 0B 01 00 00 07 81
					39 00 00 40 00 00 02 6F 1E
					39 00 00 40 00 00 1F BE 19 14 0A 23 1E 05 05 00 05 0A 01 01 03 06 82 00 02 02 00 09 81 02 80 88 0B 01 00 00 07 81
					39 00 00 40 00 00 02 6F 3C
					39 00 00 40 00 00 1F BE 19 14 0A 23 1E 05 05 00 05 0A 01 01 03 06 82 00 02 02 00 09 81 02 80 88 0B 01 00 00 07 81
					39 00 00 40 00 00 06 F0 55 AA 52 08 09
					39 00 00 40 00 00 02 6F 00
					39 00 00 40 00 00 1F BF 19 18 0C 18 2C 08 02 02 0A 04 04 04 10 08 14 01 04 06 00 0C 00 00 04 89 88 02 02 05 02 0A
					39 00 00 40 00 00 02 6F 1E
					39 00 00 40 00 00 1F BF 19 18 0C 18 2C 08 02 02 0A 04 04 04 10 08 14 01 04 06 00 0C 00 00 04 89 88 02 02 05 02 0A
					39 00 00 40 00 00 02 6F 3C
					39 00 00 40 00 00 1F BF 19 18 0C 18 2C 08 02 02 0A 04 04 04 10 08 14 01 04 06 00 0C 00 00 04 89 88 02 02 05 02 0A
					// 60Hz Freq. Setting
					39 00 00 40 00 00 2D A9 01 00 44 26 27 00 00 01 00 44 28 2C 00 00 05 0A FF 02 01 C3 23 25 3F 5A 08 02 01 C3 26 27 3F 1A 02 01 C3 28 28 D4 02 01 C3 2E 2E 00
					39 00 00 40 00 00 B5 A9 02 08 E0 00 00 00 02 08 E1 02 02 20 02 08 E2 02 02 20 02 08 E1 10 10 24 02 08 E2 10 10 24 02 08 E1 1E 1E 1D 02 08 E2 1E 1E 1D 02 08 E1 2C 2C 18 02 08 E2 2C 2C 18 02 08 E1 3A 3A 10 02 08 E2 3A 3A 10 02 08 E3 3A 3A 04 02 08 E1 43 45 09 10 1A 02 08 E2 43 45 05 09 11 02 08 E3 43 45 05 0A 13 02 08 E1 48 48 08 02 08 E2 48 48 08 02 08 E3 48 48 04 02 08 E1 55 56 02 03 02 08 E2 56 56 04 02 08 E3 55 56 01 02 02 08 E1 64 64 03 02 08 E2 64 64 03 02 08 E3 62 64 01 02 03 02 08 E1 72 72 03 02 08 E2 72 72 03 02 08 E3 70 72 01 02 03 02 08 E0 00 00 01
					39 00 00 00 00 00 91 A9 01 00 68 00 00 00 02 01 DD 02 03 00 00 02 04 B5 01 03 00 00 09 01 00 9D 00 00 AA 02 08 B0 00 00 00 01 00 A2 00 47 13 02 09 BD 00 00 04 00 00 00 00 00 00 00 02 08 B7 20 27 08 00 08 00 07 B3 07 B3 02 08 B7 28 2D 07 CC 07 CC 08 00 00 00 02 08 B0 00 00 00 00 00 00 00 00 00 00 01 00 2F 00 00 04 00 00 00 00 00 00 00 02 01 B9 20 20 4A 01 00 8D 02 02 01 01 00 A3 00 0F 82 00 00 00 00 02 01 B9 20 20 4A 00 00 00 00 00 01 00 A3 10 11 00 00
				];

			};
			timing@sdc_fhd_144 {
				#include "dsi-panel-AE106-P-1-A0037-common.dtsi"
				#include "dsi-panel-AE106-P-1-A0037-common-effect.dtsi"
				qcom,mdss-mdp-transfer-time-us = <6100>;
				qcom,mdss-dsi-timing-default;
				qcom,mdss-dsi-panel-framerate = <144>;
				qcom,mdss-dsi-panel-clockrate = <1153600000>;
				qcom,mdss-dsi-panel-width = <1272>;
				qcom,mdss-dsi-panel-height = <2772>;

				qcom,mdss-dsi-h-front-porch = <16>;
				qcom,mdss-dsi-h-back-porch = <16>;
				qcom,mdss-dsi-h-pulse-width = <2>;
				qcom,mdss-dsi-v-back-porch = <28>;
				qcom,mdss-dsi-v-front-porch = <78>;
				qcom,mdss-dsi-v-pulse-width = <2>;
				qcom,mdss-dsi-h-sync-pulse = <0>;

				oplus,ofp-need-to-sync-data-in-aod-unlocking;
				oplus,ofp-aod-off-insert-black-frame = <1>;
				oplus,ofp-aod-off-black-frame-total-time = <42>;
				oplus,ofp-need-to-separate-backlight;
				oplus,ofp-backlight-on-period = <1>;

				qcom,mdss-dsi-timing-switch-command = [
					39 00 00 40 00 00 2D A9 01 00 44 26 27 00 00 01 00 44 28 2C 00 00 08 0B 28 02 01 C3 23 25 3F 25 06 02 01 C3 26 27 3F 61 02 01 C3 28 28 D4 02 01 C3 2E 2E 00
					39 00 00 40 00 00 B5 A9 02 08 E0 00 00 00 02 08 E1 02 02 34 02 08 E2 02 02 34 02 08 E1 10 10 24 02 08 E2 10 10 24 02 08 E1 1E 1E 1D 02 08 E2 1E 1E 1D 02 08 E1 2C 2C 16 02 08 E2 2C 2C 18 02 08 E1 3A 3A 0C 02 08 E2 3A 3A 13 02 08 E3 3A 3A 04 02 08 E1 43 45 04 06 08 02 08 E2 43 45 02 04 05 02 08 E3 43 45 02 04 06 02 08 E1 48 48 01 02 08 E2 48 48 08 02 08 E3 48 48 03 02 08 E1 55 56 02 02 02 08 E2 56 56 04 02 08 E3 55 56 01 02 02 08 E1 64 64 03 02 08 E2 64 64 03 02 08 E3 62 64 01 02 03 02 08 E1 72 72 03 02 08 E2 72 72 03 02 08 E3 70 72 01 02 03 02 08 E0 00 00 01
					39 00 00 00 00 00 91 A9 01 00 68 00 00 00 02 01 DD 02 03 00 00 02 04 B5 01 03 00 00 09 01 00 9D 00 00 AA 02 08 B0 00 00 00 01 00 A2 00 47 13 02 09 BD 00 00 04 00 00 00 00 00 00 00 02 08 B7 20 27 07 C4 07 C4 07 E1 07 E1 02 08 B7 28 2D 08 62 08 62 08 BE 00 00 02 08 B0 00 00 00 00 00 00 00 00 00 00 01 00 2F 00 00 02 00 00 00 00 00 00 00 02 01 B9 1E 1E 4A 01 00 8D 02 02 01 01 00 A3 00 0F 82 00 00 00 00 02 01 B9 1E 1E 4A 00 00 00 00 00 01 00 A3 10 11 00 00
				];
				qcom,mdss-dsi-on-command = [
					// Flash lock and reload
					39 00 00 40 00 00 06 F0 55 AA 52 08 04
					39 00 00 40 00 00 02 6F 03
					39 00 00 40 00 00 02 B5 0B
					39 00 00 40 00 00 02 C0 20
					39 00 00 40 00 00 02 C1 1C
					39 00 00 40 00 00 02 C0 80
					// DMR LUT SET
					39 00 00 40 00 00 02 C0 40
					39 00 00 40 00 00 06 F0 55 AA 52 08 00
					39 00 00 40 00 00 02 6F 31
					39 00 00 40 00 00 04 C0 01 02 10
					39 00 00 40 00 00 02 6F 08
					39 00 00 40 00 00 04 C7 98 97 80
					// APL BLK setting
					39 00 00 40 00 00 06 F0 55 AA 52 08 00
					39 00 00 40 00 00 02 6F 78
					39 00 00 40 00 00 18 B0 11 00 2A 00 C2 01 DA 03 7C 05 B1 08 80 0B EE 0F FF 05 55 05 56 05 55
					39 00 00 40 00 00 02 6F 6F
					39 00 00 40 00 00 07 B0 02 7C 04 F8 02 7C
					39 00 00 40 00 00 06 F0 55 AA 52 08 08
					39 00 00 40 00 00 17 C1 9D 4F DD 4F 4F DD 4F 4F DD 4F 4F DD 4F 4F BD 4F AC BB AC 9E 0D FF
					39 00 00 40 00 00 02 6F 1D
					39 00 00 40 00 00 04 C1 00 FF FF
					39 00 00 40 00 00 02 6F 20
					39 00 00 40 00 00 04 C1 3F 33 FF
					39 00 00 40 00 00 02 6F 23
					39 00 00 40 00 00 15 C1 0D 4F DD 4F 4F DD 4F 4F DD 4F 4F DD 4F 4F BD 4F AC BB AC 9E
					39 00 00 40 00 00 02 6F 37
					39 00 00 40 00 00 15 C1 0E FF EE FF FF EE FF FF EE FF FF EE FF FF DE FF 27 DD 27 27
					39 00 00 40 00 00 02 6F 4B
					39 00 00 40 00 00 15 C1 0D 4F DD 4F 4F DD 4F 4F DD 4F 4F DD 4F 4F BD 4F AC BB AC 9E
					39 00 00 40 00 00 02 6F 5F
					39 00 00 40 00 00 15 C1 0F FF FF FF FF FF FF FF FF FF FF FF FF FF FF FF FF FF FF FF
					39 00 00 40 00 00 02 6F 73
					39 00 00 40 00 00 15 C1 0D 4F DD 4F 4F DD 4F 4F DD 4F 4F DD 4F 4F BD 4F AC BB AC 9E
					39 00 00 40 00 00 2D BA 00 01 00 8A 00 8A 01 1E 01 1E 01 9D 01 9D 02 44 02 44 03 25 03 25 04 02 04 02 04 13 04 13 06 98 06 98 0A E2 0A E2 0D BB 0D BB 0F FE
					39 00 00 40 00 00 02 6F 07
					39 00 00 40 00 00 02 51 00
					39 00 00 40 00 00 05 FF AA 55 A5 80
					// Power on/off sequence related
					39 00 00 40 00 00 02 6F 08
					39 00 00 40 00 00 02 F6 54
					39 00 00 40 00 00 02 6F 0A
					39 00 00 40 00 00 07 F6 70 70 70 70 70 70
					// DMR flashing optimization
					39 00 00 40 00 00 05 FF AA 55 A5 81
					39 00 00 40 00 00 02 6F 0D
					39 00 00 40 00 00 02 FD 40
					// Charge Pump from 2uA to 4uA
					39 00 00 40 00 00 05 FF AA 55 A5 80
					39 00 00 40 00 00 02 6F 07
					39 00 00 40 00 00 02 F8 4D
					39 00 00 40 00 00 02 6F 23
					39 00 00 40 00 00 02 F8 4D
					// TE ON
					39 00 00 40 00 00 02 35 00
					//TE1F ON
					39 00 00 40 00 00 02 6F 15
					39 00 00 40 00 00 02 35 60
					39 00 00 40 00 00 02 6F 26
					39 00 00 40 00 00 08 44 00 00 00 00 08 0B 28
					// BC Dimming OFF
					39 00 00 40 00 00 02 53 20
					// Normal DBV setting
					39 00 00 40 00 00 03 51 00 00
					// Idle DBV Setting
					39 00 00 40 00 00 02 6F 04
					39 00 00 40 00 00 03 51 0D DA
					// H_res = 1272  V_res = 2772
					39 00 00 40 00 00 05 2A 00 00 04 F7
					39 00 00 40 00 00 05 2B 00 00 0A D3
					// Compression method selection 10_8 2dsc & slice high 12 & vesa 1.2
					39 00 00 40 00 00 02 90 03
					39 00 00 40 00 00 02 6F 01
					39 00 00 40 00 00 02 90 43
					39 00 00 40 00 00 13 91 AB A8 00 0C C2 00 02 3E 01 37 00 08 08 BB 07 32 10 F0
					// GPIO Setting
					39 00 00 40 00 00 06 F0 55 AA 52 08 00
					39 00 00 40 00 00 05 BE 5F 4C 47 49
					// Round curve control
					39 00 00 40 00 00 06 F0 55 AA 52 08 07
					39 00 00 40 00 00 0E B8 01 00 F5 09 C8 00 00 00 00 00 00 00 00
					39 00 00 40 00 00 04 C0 A7 01 09
					39 00 00 40 00 00 02 6F 03
					39 00 00 40 00 00 05 C0 00 00 00 00
					39 00 00 40 00 00 16 C1 B0 0F 00 24 09 00 FD C0 3F FF DD B0 3F FE 6D 28 00 00 08 2D 10
					39 00 00 40 00 00 02 6F 15
					39 00 00 40 00 00 11 C1 06 01 94 0E 00 00 06 33 F0 FA 86 02 DC 00 00 00
					39 00 00 40 00 00 02 6F 25
					39 00 00 40 00 00 08 C1 00 00 05 00 8A 98 00
					39 00 00 40 00 00 16 C2 B0 0F 26 49 29 71 B0 56 3F C1 8B B2 3F C0 4D 0A 00 17 08 B0 2C
					39 00 00 40 00 00 02 6F 15
					39 00 00 40 00 00 11 C2 3D 00 06 93 00 05 97 43 F0 6F 73 4F DD C0 00 FF
					39 00 00 40 00 00 02 6F 25
					39 00 00 40 00 00 08 C2 00 90 93 00 00 05 00
					39 00 00 40 00 00 16 C3 B8 0F 05 A4 00 10 FE D0 3F FF 44 E0 3F FF F0 28 00 00 03 97 B0
					39 00 00 40 00 00 02 6F 15
					39 00 00 40 00 00 11 C3 5A 00 00 06 00 98 F2 33 F0 A6 FA 02 1C 00 00 00
					39 00 00 40 00 00 02 6F 25
					39 00 00 40 00 00 08 C3 44 64 67 00 00 05 00
					39 00 00 40 00 00 16 C4 BC 00 13 24 00 40 04 60 3F FB 1E 00 00 00 00 00 00 00 00 00 00
					39 00 00 40 00 00 02 6F 15
					39 00 00 40 00 00 11 C4 82 00 00 08 9A CB 4D 33 C0 7E 08 00 00 00 00 00
					39 00 00 40 00 00 02 6F 25
					39 00 00 40 00 00 08 C4 44 F2 F7 00 91 97 00
					39 00 00 40 00 00 16 C5 BC 00 17 C4 1A E9 32 94 3F BD 81 A4 00 10 C8 E8 00 00 00 00 00
					39 00 00 40 00 00 02 6F 15
					39 00 00 40 00 00 11 C5 50 00 08 8F AA 4E CE 33 C0 80 87 00 00 00 00 00
					39 00 00 40 00 00 02 6F 25
					39 00 00 40 00 00 08 C5 00 01 07 AA 4D 57 00
					39 00 00 40 00 00 16 C6 B4 00 00 01 01 B9 00 2A 3F FF FC 58 00 00 12 48 00 00 00 00 00
					39 00 00 40 00 00 02 6F 15
					39 00 00 40 00 00 11 C6 05 00 90 C3 AA CE D3 33 C0 FB 33 00 00 00 00 00
					39 00 00 40 00 00 02 6F 25
					39 00 00 40 00 00 08 C6 00 88 90 AA CF D3 00
					39 00 00 40 00 00 16 C7 31 00 05 A4 05 A4 00 00 3F FE 53 50 3F FE 53 50 00 00 1F D1 10
					39 00 00 40 00 00 02 6F 15
					39 00 00 40 00 00 11 C7 0B 22 55 7B 00 2C 52 33 F0 DA DA 05 A4 00 00 00
					39 00 00 40 00 00 02 6F 25
					39 00 00 40 00 00 08 C7 44 F0 F7 AA 4D 54 00
					39 00 00 40 00 00 16 C8 3D 00 05 A4 05 A4 00 00 3F FE 53 50 00 00 00 00 00 00 00 00 00
					39 00 00 40 00 00 02 6F 15
					39 00 00 40 00 00 11 C8 1A 22 55 7B 00 53 79 33 C0 DA 26 00 00 00 00 00
					39 00 00 40 00 00 02 6F 25
					39 00 00 40 00 00 08 C8 44 69 70 AA CF D3 00
					39 00 00 40 00 00 16 C9 27 00 05 A4 05 A4 00 00 00 00 00 00 3F FE 53 50 00 00 00 00 00
					39 00 00 40 00 00 02 6F 15
					39 00 00 40 00 00 11 C9 0B 22 7C A2 00 2C 52 33 30 26 DA 00 00 00 00 00
					39 00 00 40 00 00 02 6F 25
					39 00 00 40 00 00 08 C9 00 00 00 00 00 00 00
					39 00 00 40 00 00 16 CA 2B 00 05 A4 05 A4 00 00 00 00 00 00 00 00 00 00 7F FF E0 2E F0
					39 00 00 40 00 00 02 6F 15
					39 00 00 40 00 00 11 CA 1A 22 7C A2 00 53 79 33 0F 26 26 FA 5C 00 00 00
					39 00 00 40 00 00 02 6F 25
					39 00 00 40 00 00 08 CA 00 00 00 00 00 00 00
					39 00 00 40 00 00 16 CB 00 00 00 00 00 00 00 00 00 00 00 00 00 00 00 00 00 00 00 00 00
					39 00 00 40 00 00 02 6F 15
					39 00 00 40 00 00 11 CB 00 00 00 00 00 00 00 00 00 00 00 00 00 00 00 00
					39 00 00 40 00 00 02 6F 25
					39 00 00 40 00 00 08 CB 00 00 00 00 00 00 00
					39 00 00 40 00 00 16 CC 00 00 00 00 00 00 00 00 00 00 00 00 00 00 00 00 00 00 00 00 00
					39 00 00 40 00 00 02 6F 15
					39 00 00 40 00 00 11 CC 00 00 00 00 00 00 00 00 00 00 00 00 00 00 00 00
					39 00 00 40 00 00 02 6F 25
					39 00 00 40 00 00 08 CC 00 00 00 00 00 00 00
					39 00 00 40 00 00 16 CD 00 00 00 00 00 00 00 00 00 00 00 00 00 00 00 00 00 00 00 00 00
					39 00 00 40 00 00 02 6F 15
					39 00 00 40 00 00 11 CD 00 00 00 00 00 00 00 00 00 00 00 00 00 00 00 00
					39 00 00 40 00 00 02 6F 25
					39 00 00 40 00 00 08 CD 00 00 00 00 00 00 00
					39 00 00 40 00 00 16 CE 00 00 00 00 00 00 00 00 00 00 00 00 00 00 00 00 00 00 00 00 00
					39 00 00 40 00 00 02 6F 15
					39 00 00 40 00 00 11 CE 00 00 00 00 00 00 00 00 00 00 00 00 00 00 00 00
					39 00 00 40 00 00 02 6F 25
					39 00 00 40 00 00 08 CE 00 00 00 00 00 00 00
					39 00 00 40 00 00 16 CF 00 00 00 00 00 00 00 00 00 00 00 00 00 00 00 00 00 00 00 00 00
					39 00 00 40 00 00 02 6F 15
					39 00 00 40 00 00 11 CF 00 00 00 00 00 00 00 00 00 00 00 00 00 00 00 00
					39 00 00 40 00 00 02 6F 25
					39 00 00 40 00 00 08 CF 00 00 00 00 00 00 00
					39 00 00 40 00 00 16 D0 00 00 00 00 00 00 00 00 00 00 00 00 00 00 00 00 00 00 00 00 00
					39 00 00 40 00 00 02 6F 15
					39 00 00 40 00 00 11 D0 00 00 00 00 00 00 00 00 00 00 00 00 00 00 00 00
					39 00 00 40 00 00 02 6F 25
					39 00 00 40 00 00 08 D0 00 00 00 00 00 00 00
					39 00 00 40 00 00 0F D1 80 00 00 00 00 04 F8 80 00 6B BD 09 04 F7
					39 00 00 40 00 00 02 6F 0E
					39 00 00 40 00 00 0F D1 80 00 00 00 00 04 F7 FF FF DD B9 00 04 F7
					39 00 00 40 00 00 02 6F 1C
					39 00 00 40 00 00 0F D1 FF E3 8B 46 00 04 F7 FF FF FF 4F B1 04 F8
					39 00 00 40 00 00 02 6F 2A
					39 00 00 40 00 00 0C D1 00 00 00 00 00 04 F8 7F FF E0 2E
					39 00 00 40 00 00 12 D2 F0 04 F8 00 00 1F D1 10 04 F8 00 00 00 00 00 04 F8
					//RCN
					39 00 00 40 00 00 06 F0 55 AA 52 08 07
					39 00 00 40 00 00 02 C0 A7
					//OSC trim
					39 00 00 40 00 00 06 F0 55 AA 52 08 01
					39 00 00 40 00 00 36 C3 99 29 02 6B 19 00 29 00 6B 19 00 3F 5A 08 3F 1A D4 3F 2A 07 3F 28 D4 3F 25 06 3F 61 D4 3F 3B 46 3F 46 07 3F 5A 08 3F 1A D4 11 11 01 00 10 00 77 00 AA 02 AA 02
					39 00 00 40 00 00 06 F0 55 AA 52 08 01
					39 00 00 40 00 00 07 B3 44 44 44 44 44 44
					39 00 00 40 00 00 06 F0 55 AA 52 08 07
					39 00 00 40 00 00 0E B4 C0 50 60 60 50 35 80 20 60 58 80 38 70
					//OD
					39 00 00 40 00 00 06 F0 55 AA 52 08 08
					39 00 00 40 00 00 05 E0 01 01 81 01
					39 00 00 40 00 00 02 6F 06
					39 00 00 40 00 00 0E E0 80 00 21 32 43 54 65 66 66 76 87 98 99
					39 00 00 40 00 00 06 F0 55 AA 52 08 08
					39 00 00 40 00 00 02 6F 04
					39 00 00 40 00 00 02 E0 20
					39 00 00 40 00 00 02 6F 1B
					39 00 00 40 00 00 04 EB 44 00 00
					39 00 00 40 00 00 02 6F 1E
					39 00 00 40 00 00 04 EB 94 00 00
					39 00 00 40 00 00 02 6F 21
					39 00 00 40 00 00 03 EB 04 00
					39 00 00 40 00 00 02 6F 24
					39 00 00 40 00 00 04 EB 10 32 54
					39 00 00 40 00 00 0F E1 03 04 34 00 00 00 00 00 00 00 00 00 00 00
					39 00 00 40 00 00 0F E2 03 04 34 00 00 00 00 00 00 00 00 00 00 00
					39 00 00 40 00 00 0F E3 00 00 00 00 00 00 00 00 00 00 00 00 00 00
					39 00 00 40 00 00 02 6F 0E
					39 00 00 40 00 00 0F E1 02 04 24 03 03 03 03 03 03 03 03 08 0F 1A
					39 00 00 40 00 00 02 6F 0E
					39 00 00 40 00 00 0F E2 03 04 24 03 03 03 03 03 03 03 03 09 0E 17
					39 00 00 40 00 00 02 6F 0E
					39 00 00 40 00 00 0F E3 03 04 06 03 03 03 03 03 03 04 03 09 0E 07
					39 00 00 40 00 00 02 6F 1C
					39 00 00 40 00 00 0F E1 01 03 1D 03 03 03 03 03 03 03 03 03 08 0F
					39 00 00 40 00 00 02 6F 1C
					39 00 00 40 00 00 0F E2 02 03 1D 04 04 04 04 04 04 04 04 04 07 0C
					39 00 00 40 00 00 02 6F 1C
					39 00 00 40 00 00 0F E3 02 03 05 04 04 04 04 04 04 04 04 03 07 12
					39 00 00 40 00 00 02 6F 2A
					39 00 00 40 00 00 0F E1 01 03 16 04 04 04 04 04 04 04 04 04 07 0E
					39 00 00 40 00 00 02 6F 2A
					39 00 00 40 00 00 0F E2 02 03 18 03 03 03 03 03 03 03 03 03 06 0D
					39 00 00 40 00 00 02 6F 2A
					39 00 00 40 00 00 0F E3 01 01 04 03 03 03 03 03 03 03 03 05 0B 13
					39 00 00 40 00 00 02 6F 38
					39 00 00 40 00 00 0F E1 02 04 0C 04 04 04 04 04 04 04 04 04 06 08
					39 00 00 40 00 00 02 6F 38
					39 00 00 40 00 00 0F E2 03 04 13 04 04 04 04 04 04 04 04 02 04 05
					39 00 00 40 00 00 02 6F 38
					39 00 00 40 00 00 0F E3 01 01 04 04 04 04 04 04 04 04 05 02 04 06
					39 00 00 40 00 00 02 6F 46
					39 00 00 40 00 00 0F E1 02 04 01 03 03 03 03 03 05 05 05 05 05 10
					39 00 00 40 00 00 02 6F 46
					39 00 00 40 00 00 0F E2 03 04 08 03 03 03 03 03 04 04 04 04 04 06
					39 00 00 40 00 00 02 6F 46
					39 00 00 40 00 00 0F E3 01 01 03 03 03 03 03 03 04 04 04 04 04 06
					39 00 00 40 00 00 02 6F 54
					39 00 00 40 00 00 0F E1 01 02 02 04 05 05 05 03 03 03 02 02 02 02
					39 00 00 40 00 00 02 6F 54
					39 00 00 40 00 00 0F E2 01 02 04 04 04 05 05 02 02 01 01 01 01 01
					39 00 00 40 00 00 02 6F 54
					39 00 00 40 00 00 0F E3 00 01 02 02 04 05 05 02 02 01 01 01 01 01
					39 00 00 40 00 00 02 6F 62
					39 00 00 40 00 00 0F E1 01 02 03 04 04 04 04 03 03 03 02 02 02 02
					39 00 00 40 00 00 02 6F 62
					39 00 00 40 00 00 0F E2 01 02 03 03 03 03 03 02 02 01 01 01 01 01
					39 00 00 40 00 00 02 6F 62
					39 00 00 40 00 00 0F E3 01 02 03 03 03 03 03 02 02 01 01 01 01 01
					39 00 00 40 00 00 02 6F 70
					39 00 00 40 00 00 0F E1 01 02 03 04 04 04 04 03 03 03 02 02 02 02
					39 00 00 40 00 00 02 6F 70
					39 00 00 40 00 00 0F E2 01 02 03 04 05 04 04 02 02 02 01 01 01 01
					39 00 00 40 00 00 02 6F 70
					39 00 00 40 00 00 0F E3 01 02 03 04 05 04 04 02 02 02 01 01 01 01
					// Sleep out
					15 00 00 00 78 00 02 11 00
					// Display on
					15 00 00 00 00 00 02 29 00
					39 00 00 40 00 00 02 68 00
					39 00 00 40 00 00 06 F0 55 AA 52 08 00
					39 00 00 40 00 00 02 6F 04
					39 00 00 40 00 00 02 B1 00
					39 00 00 40 00 00 02 6F 2A
					39 00 00 40 00 00 02 BB 00
					39 00 00 40 00 00 02 6F 30
					39 00 00 40 00 00 02 C0 3F
					39 00 00 40 00 00 06 F0 55 AA 52 08 09
					39 00 00 40 00 00 02 BD 04
					39 00 00 40 00 00 02 6F 01
					39 00 00 40 00 00 0A BD 31 9D 25 54 13 14 A6 98 E2
					39 00 00 40 00 00 02 6F 0A
					39 00 00 40 00 00 06 BD 10 20 40 80 FF
					39 00 00 40 00 00 02 6F 1A
					39 00 00 40 00 00 06 BD FF FF FF FF FF
					39 00 00 40 00 00 02 6F 10
					39 00 00 40 00 00 04 BD FD 07 00
					39 00 00 40 00 00 02 6F 16
					39 00 00 40 00 00 02 BD 15
					39 00 00 40 00 00 06 F0 55 AA 52 08 09
					39 00 00 40 00 00 02 6F 00
					39 00 00 40 00 00 1F BE 19 14 0A 23 1E 05 05 00 05 0A 01 01 03 06 82 00 02 02 00 09 81 02 80 88 0B 01 00 00 07 81
					39 00 00 40 00 00 02 6F 1E
					39 00 00 40 00 00 1F BE 19 14 0A 23 1E 05 05 00 05 0A 01 01 03 06 82 00 02 02 00 09 81 02 80 88 0B 01 00 00 07 81
					39 00 00 40 00 00 02 6F 3C
					39 00 00 40 00 00 1F BE 19 14 0A 23 1E 05 05 00 05 0A 01 01 03 06 82 00 02 02 00 09 81 02 80 88 0B 01 00 00 07 81
					39 00 00 40 00 00 06 F0 55 AA 52 08 09
					39 00 00 40 00 00 02 6F 00
					39 00 00 40 00 00 1F BF 19 18 0C 18 2C 08 02 02 0A 04 04 04 10 08 14 01 04 06 00 0C 00 00 04 89 88 02 02 05 02 0A
					39 00 00 40 00 00 02 6F 1E
					39 00 00 40 00 00 1F BF 19 18 0C 18 2C 08 02 02 0A 04 04 04 10 08 14 01 04 06 00 0C 00 00 04 89 88 02 02 05 02 0A
					39 00 00 40 00 00 02 6F 3C
					39 00 00 40 00 00 1F BF 19 18 0C 18 2C 08 02 02 0A 04 04 04 10 08 14 01 04 06 00 0C 00 00 04 89 88 02 02 05 02 0A
					// 144Hz Freq. Setting
					39 00 00 40 00 00 2D A9 01 00 44 26 27 00 00 01 00 44 28 2C 00 00 08 0B 28 02 01 C3 23 25 3F 25 06 02 01 C3 26 27 3F 61 02 01 C3 28 28 D4 02 01 C3 2E 2E 00
					39 00 00 40 00 00 B5 A9 02 08 E0 00 00 00 02 08 E1 02 02 34 02 08 E2 02 02 34 02 08 E1 10 10 24 02 08 E2 10 10 24 02 08 E1 1E 1E 1D 02 08 E2 1E 1E 1D 02 08 E1 2C 2C 16 02 08 E2 2C 2C 18 02 08 E1 3A 3A 0C 02 08 E2 3A 3A 13 02 08 E3 3A 3A 04 02 08 E1 43 45 04 06 08 02 08 E2 43 45 02 04 05 02 08 E3 43 45 02 04 06 02 08 E1 48 48 01 02 08 E2 48 48 08 02 08 E3 48 48 03 02 08 E1 55 56 02 02 02 08 E2 56 56 04 02 08 E3 55 56 01 02 02 08 E1 64 64 03 02 08 E2 64 64 03 02 08 E3 62 64 01 02 03 02 08 E1 72 72 03 02 08 E2 72 72 03 02 08 E3 70 72 01 02 03 02 08 E0 00 00 01
					39 00 00 00 00 00 91 A9 01 00 68 00 00 00 02 01 DD 02 03 00 00 02 04 B5 01 03 00 00 09 01 00 9D 00 00 AA 02 08 B0 00 00 00 01 00 A2 00 47 13 02 09 BD 00 00 04 00 00 00 00 00 00 00 02 08 B7 20 27 07 C4 07 C4 07 E1 07 E1 02 08 B7 28 2D 08 62 08 62 08 BE 00 00 02 08 B0 00 00 00 00 00 00 00 00 00 00 01 00 2F 00 00 02 00 00 00 00 00 00 00 02 01 B9 1E 1E 4A 01 00 8D 02 02 01 01 00 A3 00 0F 82 00 00 00 00 02 01 B9 1E 1E 4A 00 00 00 00 00 01 00 A3 10 11 00 00
				];

			};
			timing@sdc_fhd_165 {
				#include "dsi-panel-AE106-P-1-A0037-common.dtsi"
				#include "dsi-panel-AE106-P-1-A0037-common-effect.dtsi"
				qcom,mdss-mdp-transfer-time-us = <5380>;
				qcom,mdss-dsi-timing-default;
				qcom,mdss-dsi-panel-framerate = <165>;
				qcom,mdss-dsi-panel-clockrate = <1434000000>;
				qcom,mdss-dsi-panel-width = <1272>;
				qcom,mdss-dsi-panel-height = <2772>;

				qcom,mdss-dsi-h-front-porch = <26>;
				qcom,mdss-dsi-h-back-porch = <26>;
				qcom,mdss-dsi-h-pulse-width = <2>;
				qcom,mdss-dsi-v-back-porch = <24>;
				qcom,mdss-dsi-v-front-porch = <56>;
				qcom,mdss-dsi-v-pulse-width = <2>;
				qcom,mdss-dsi-h-sync-pulse = <0>;

				oplus,ofp-need-to-sync-data-in-aod-unlocking;
				oplus,ofp-aod-off-insert-black-frame = <1>;
				oplus,ofp-aod-off-black-frame-total-time = <42>;
				oplus,ofp-need-to-separate-backlight;
				oplus,ofp-backlight-on-period = <1>;

				qcom,mdss-dsi-timing-switch-command = [
				];
                qcom,mdss-dsi-fps-switch-60-to-165-command = [
					39 00 00 40 00 00 2D A9 01 00 44 26 27 00 00 01 00 44 28 2C 00 00 08 0B 38 02 01 C3 23 25 3F 3B 46 02 01 C3 26 27 3F 46 02 01 C3 28 28 07 02 01 C3 2E 2E 01
					39 00 00 40 00 00 B5 A9 02 08 E0 00 00 00 02 08 E1 02 02 20 02 08 E2 02 02 20 02 08 E1 10 10 17 02 08 E2 10 10 1A 02 08 E1 1E 1E 0F 02 08 E2 1E 1E 12 02 08 E1 2C 2C 0C 02 08 E2 2C 2C 0D 02 08 E1 3A 3A 07 02 08 E2 3A 3A 08 02 08 E3 3A 3A 03 02 08 E1 43 45 09 10 1A 02 08 E2 43 45 05 09 11 02 08 E3 43 45 05 0A 13 02 08 E1 48 48 03 02 08 E2 48 48 04 02 08 E3 48 48 04 02 08 E1 55 56 01 01 02 08 E2 56 56 02 02 08 E3 55 56 00 00 02 08 E1 64 64 02 02 08 E2 64 64 02 02 08 E3 62 64 00 00 00 02 08 E1 72 72 02 02 08 E2 72 72 02 02 08 E3 70 72 00 00 00 02 08 E0 00 00 01
					39 00 00 00 00 00 91 A9 01 00 68 00 00 00 02 01 DD 02 03 04 85 02 04 B5 01 03 00 00 86 01 00 9D 00 00 AA 02 08 B0 00 00 00 01 00 A2 00 47 13 02 09 BD 00 00 04 00 00 00 00 00 00 00 02 08 B7 20 27 09 3E 09 3E 0B 03 0B 03 02 08 B7 28 2D 0B 5A 0B 5A 0B 09 00 00 02 08 B0 00 00 00 00 00 00 00 00 00 00 01 00 2F 00 00 03 00 00 00 00 00 00 00 02 01 B9 1F 1F 4A 01 00 8D 02 02 01 01 00 A3 00 0F 82 00 00 00 00 02 01 B9 1F 1F 4A 00 00 00 00 00 01 00 A3 10 11 00 00
				];
				qcom,mdss-dsi-fps-switch-90-to-165-command = [
					39 00 00 40 00 00 2D A9 01 00 44 26 27 00 00 01 00 44 28 2C 00 00 08 0B 38 02 01 C3 23 25 3F 3B 46 02 01 C3 26 27 3F 46 02 01 C3 28 28 07 02 01 C3 2E 2E 01
					39 00 00 40 00 00 B5 A9 02 08 E0 00 00 00 02 08 E1 02 02 20 02 08 E2 02 02 20 02 08 E1 10 10 17 02 08 E2 10 10 1A 02 08 E1 1E 1E 0F 02 08 E2 1E 1E 12 02 08 E1 2C 2C 0C 02 08 E2 2C 2C 0D 02 08 E1 3A 3A 07 02 08 E2 3A 3A 08 02 08 E3 3A 3A 03 02 08 E1 43 45 09 10 1A 02 08 E2 43 45 05 09 11 02 08 E3 43 45 05 0A 13 02 08 E1 48 48 03 02 08 E2 48 48 04 02 08 E3 48 48 04 02 08 E1 55 56 01 01 02 08 E2 56 56 02 02 08 E3 55 56 00 00 02 08 E1 64 64 02 02 08 E2 64 64 02 02 08 E3 62 64 00 00 00 02 08 E1 72 72 02 02 08 E2 72 72 02 02 08 E3 70 72 00 00 00 02 08 E0 00 00 01
					39 00 00 00 00 00 91 A9 01 00 68 00 00 00 02 01 DD 02 03 04 85 02 04 B5 01 03 00 00 86 01 00 9D 00 00 AA 02 08 B0 00 00 00 01 00 A2 00 47 13 02 09 BD 00 00 04 00 00 00 00 00 00 00 02 08 B7 20 27 09 3E 09 3E 0B 03 0B 03 02 08 B7 28 2D 0B 5A 0B 5A 0B 09 00 00 02 08 B0 00 00 00 00 00 00 00 00 00 00 01 00 2F 00 00 03 00 00 00 00 00 00 00 02 01 B9 1F 1F 6A 01 00 8D 02 02 01 01 00 A3 00 0F 82 00 00 00 00 02 01 B9 1F 1F 4A 00 00 00 00 00 01 00 A3 10 11 00 00
				];
				qcom,mdss-dsi-fps-switch-120-to-165-command = [
					39 00 00 40 00 00 2D A9 01 00 44 26 27 00 00 01 00 44 28 2C 00 00 08 0B 38 02 01 C3 23 25 3F 3B 46 02 01 C3 26 27 3F 46 02 01 C3 28 28 07 02 01 C3 2E 2E 01
					39 00 00 40 00 00 B5 A9 02 08 E0 00 00 00 02 08 E1 02 02 20 02 08 E2 02 02 20 02 08 E1 10 10 17 02 08 E2 10 10 1A 02 08 E1 1E 1E 0F 02 08 E2 1E 1E 12 02 08 E1 2C 2C 0C 02 08 E2 2C 2C 0D 02 08 E1 3A 3A 07 02 08 E2 3A 3A 08 02 08 E3 3A 3A 03 02 08 E1 43 45 09 10 1A 02 08 E2 43 45 05 09 11 02 08 E3 43 45 05 0A 13 02 08 E1 48 48 03 02 08 E2 48 48 04 02 08 E3 48 48 04 02 08 E1 55 56 01 01 02 08 E2 56 56 02 02 08 E3 55 56 00 00 02 08 E1 64 64 02 02 08 E2 64 64 02 02 08 E3 62 64 00 00 00 02 08 E1 72 72 02 02 08 E2 72 72 02 02 08 E3 70 72 00 00 00 02 08 E0 00 00 01
					39 00 00 00 00 00 91 A9 01 00 68 00 00 00 02 01 DD 02 03 04 85 02 04 B5 01 03 00 00 86 01 00 9D 00 00 AA 02 08 B0 00 00 00 01 00 A2 00 47 13 02 09 BD 00 00 04 00 00 00 00 00 00 00 02 08 B7 20 27 09 3E 09 3E 0B 03 0B 03 02 08 B7 28 2D 0B 5A 0B 5A 0B 09 00 00 02 08 B0 00 00 00 00 00 00 00 00 00 00 01 00 2F 00 00 03 00 00 00 00 00 00 00 02 01 B9 1F 1F 6A 01 00 8D 02 02 01 01 00 A3 00 0F 82 00 00 00 00 02 01 B9 1F 1F 4A 00 00 00 00 00 01 00 A3 10 11 00 00
				];
				qcom,mdss-dsi-fps-switch-144-to-165-command = [
					39 00 00 40 00 00 2D A9 01 00 44 26 27 00 00 01 00 44 28 2C 00 00 08 0B 38 02 01 C3 23 25 3F 3B 46 02 01 C3 26 27 3F 46 02 01 C3 28 28 07 02 01 C3 2E 2E 01
					39 00 00 40 00 00 B5 A9 02 08 E0 00 00 00 02 08 E1 02 02 20 02 08 E2 02 02 20 02 08 E1 10 10 17 02 08 E2 10 10 1A 02 08 E1 1E 1E 0F 02 08 E2 1E 1E 12 02 08 E1 2C 2C 0C 02 08 E2 2C 2C 0D 02 08 E1 3A 3A 07 02 08 E2 3A 3A 08 02 08 E3 3A 3A 03 02 08 E1 43 45 09 10 1A 02 08 E2 43 45 05 09 11 02 08 E3 43 45 05 0A 13 02 08 E1 48 48 03 02 08 E2 48 48 04 02 08 E3 48 48 04 02 08 E1 55 56 01 01 02 08 E2 56 56 02 02 08 E3 55 56 00 00 02 08 E1 64 64 02 02 08 E2 64 64 02 02 08 E3 62 64 00 00 00 02 08 E1 72 72 02 02 08 E2 72 72 02 02 08 E3 70 72 00 00 00 02 08 E0 00 00 01
					39 00 00 00 00 00 91 A9 01 00 68 00 00 00 02 01 DD 02 03 04 85 02 04 B5 01 03 00 00 86 01 00 9D 00 00 AA 02 08 B0 00 00 00 01 00 A2 00 47 13 02 09 BD 00 00 04 00 00 00 00 00 00 00 02 08 B7 20 27 09 3E 09 3E 0B 03 0B 03 02 08 B7 28 2D 0B 5A 0B 5A 0B 09 00 00 02 08 B0 00 00 00 00 00 00 00 00 00 00 01 00 2F 00 00 03 00 00 00 00 00 00 00 02 01 B9 1F 1F 4A 01 00 8D 02 02 01 01 00 A3 00 0F 82 00 00 00 00 02 01 B9 1F 1F 4A 00 00 00 00 00 01 00 A3 10 11 00 00
				];
				qcom,mdss-dsi-on-command = [
					// Flash lock and reload
					39 00 00 40 00 00 06 F0 55 AA 52 08 04
					39 00 00 40 00 00 02 6F 03
					39 00 00 40 00 00 02 B5 0B
					39 00 00 40 00 00 02 C0 20
					39 00 00 40 00 00 02 C1 1C
					39 00 00 40 00 00 02 C0 80
					// DMR LUT SET
					39 00 00 40 00 00 02 C0 40
					39 00 00 40 00 00 06 F0 55 AA 52 08 00
					39 00 00 40 00 00 02 6F 31
					39 00 00 40 00 00 04 C0 01 02 10
					39 00 00 40 00 00 02 6F 08
					39 00 00 40 00 00 04 C7 98 97 80
					// APL BLK setting
					39 00 00 40 00 00 06 F0 55 AA 52 08 00
					39 00 00 40 00 00 02 6F 78
					39 00 00 40 00 00 18 B0 11 00 2A 00 C2 01 DA 03 7C 05 B1 08 80 0B EE 0F FF 05 55 05 56 05 55
					39 00 00 40 00 00 02 6F 6F
					39 00 00 40 00 00 07 B0 02 7C 04 F8 02 7C
					39 00 00 40 00 00 06 F0 55 AA 52 08 08
					39 00 00 40 00 00 17 C1 9D 4F DD 4F 4F DD 4F 4F DD 4F 4F DD 4F 4F BD 4F AC BB AC 9E 0D FF
					39 00 00 40 00 00 02 6F 1D
					39 00 00 40 00 00 04 C1 00 FF FF
					39 00 00 40 00 00 02 6F 20
					39 00 00 40 00 00 04 C1 3F 33 FF
					39 00 00 40 00 00 02 6F 23
					39 00 00 40 00 00 15 C1 0D 4F DD 4F 4F DD 4F 4F DD 4F 4F DD 4F 4F BD 4F AC BB AC 9E
					39 00 00 40 00 00 02 6F 37
					39 00 00 40 00 00 15 C1 0E FF EE FF FF EE FF FF EE FF FF EE FF FF DE FF 27 DD 27 27
					39 00 00 40 00 00 02 6F 4B
					39 00 00 40 00 00 15 C1 0D 4F DD 4F 4F DD 4F 4F DD 4F 4F DD 4F 4F BD 4F AC BB AC 9E
					39 00 00 40 00 00 02 6F 5F
					39 00 00 40 00 00 15 C1 0F FF FF FF FF FF FF FF FF FF FF FF FF FF FF FF FF FF FF FF
					39 00 00 40 00 00 02 6F 73
					39 00 00 40 00 00 15 C1 0D 4F DD 4F 4F DD 4F 4F DD 4F 4F DD 4F 4F BD 4F AC BB AC 9E
					39 00 00 40 00 00 2D BA 00 01 00 8A 00 8A 01 1E 01 1E 01 9D 01 9D 02 44 02 44 03 25 03 25 04 02 04 02 04 13 04 13 06 98 06 98 0A E2 0A E2 0D BB 0D BB 0F FE
					39 00 00 40 00 00 02 6F 07
					39 00 00 40 00 00 02 51 00
					39 00 00 40 00 00 05 FF AA 55 A5 80
					// Power on/off sequence related
					39 00 00 40 00 00 02 6F 08
					39 00 00 40 00 00 02 F6 54
					39 00 00 40 00 00 02 6F 0A
					39 00 00 40 00 00 07 F6 70 70 70 70 70 70
					// DMR flashing optimization
					39 00 00 40 00 00 05 FF AA 55 A5 81
					39 00 00 40 00 00 02 6F 0D
					39 00 00 40 00 00 02 FD 40
					// Charge Pump from 2uA to 4uA
					39 00 00 40 00 00 05 FF AA 55 A5 80
					39 00 00 40 00 00 02 6F 07
					39 00 00 40 00 00 02 F8 4D
					39 00 00 40 00 00 02 6F 23
					39 00 00 40 00 00 02 F8 4D
					// TE ON
					39 00 00 40 00 00 02 35 00
					//TE1F ON
					39 00 00 40 00 00 02 6F 15
					39 00 00 40 00 00 02 35 60
					39 00 00 40 00 00 02 6F 26
					39 00 00 40 00 00 08 44 00 00 00 00 08 0B 38
					// BC Dimming OFF
					39 00 00 40 00 00 02 53 20
					// Normal DBV setting
					39 00 00 40 00 00 03 51 00 00
					// Idle DBV Setting
					39 00 00 40 00 00 02 6F 04
					39 00 00 40 00 00 03 51 0D DA
					// H_res = 1272  V_res = 2772
					39 00 00 40 00 00 05 2A 00 00 04 F7
					39 00 00 40 00 00 05 2B 00 00 0A D3
					// Compression method selection 10_8 2dsc & slice high 12 & vesa 1.2
					39 00 00 40 00 00 02 90 03
					39 00 00 40 00 00 02 6F 01
					39 00 00 40 00 00 02 90 43
					39 00 00 40 00 00 13 91 AB A8 00 0C C2 00 02 3E 01 37 00 08 08 BB 07 32 10 F0
					// GPIO Setting
					39 00 00 40 00 00 06 F0 55 AA 52 08 00
					39 00 00 40 00 00 05 BE 5F 4C 47 49
					// Round curve control
					39 00 00 40 00 00 06 F0 55 AA 52 08 07
					39 00 00 40 00 00 0E B8 01 00 F5 09 C8 00 00 00 00 00 00 00 00
					39 00 00 40 00 00 04 C0 A7 01 09
					39 00 00 40 00 00 02 6F 03
					39 00 00 40 00 00 05 C0 00 00 00 00
					39 00 00 40 00 00 16 C1 B0 0F 00 24 09 00 FD C0 3F FF DD B0 3F FE 6D 28 00 00 08 2D 10
					39 00 00 40 00 00 02 6F 15
					39 00 00 40 00 00 11 C1 06 01 94 0E 00 00 06 33 F0 FA 86 02 DC 00 00 00
					39 00 00 40 00 00 02 6F 25
					39 00 00 40 00 00 08 C1 00 00 05 00 8A 98 00
					39 00 00 40 00 00 16 C2 B0 0F 26 49 29 71 B0 56 3F C1 8B B2 3F C0 4D 0A 00 17 08 B0 2C
					39 00 00 40 00 00 02 6F 15
					39 00 00 40 00 00 11 C2 3D 00 06 93 00 05 97 43 F0 6F 73 4F DD C0 00 FF
					39 00 00 40 00 00 02 6F 25
					39 00 00 40 00 00 08 C2 00 90 93 00 00 05 00
					39 00 00 40 00 00 16 C3 B8 0F 05 A4 00 10 FE D0 3F FF 44 E0 3F FF F0 28 00 00 03 97 B0
					39 00 00 40 00 00 02 6F 15
					39 00 00 40 00 00 11 C3 5A 00 00 06 00 98 F2 33 F0 A6 FA 02 1C 00 00 00
					39 00 00 40 00 00 02 6F 25
					39 00 00 40 00 00 08 C3 44 64 67 00 00 05 00
					39 00 00 40 00 00 16 C4 BC 00 13 24 00 40 04 60 3F FB 1E 00 00 00 00 00 00 00 00 00 00
					39 00 00 40 00 00 02 6F 15
					39 00 00 40 00 00 11 C4 82 00 00 08 9A CB 4D 33 C0 7E 08 00 00 00 00 00
					39 00 00 40 00 00 02 6F 25
					39 00 00 40 00 00 08 C4 44 F2 F7 00 91 97 00
					39 00 00 40 00 00 16 C5 BC 00 17 C4 1A E9 32 94 3F BD 81 A4 00 10 C8 E8 00 00 00 00 00
					39 00 00 40 00 00 02 6F 15
					39 00 00 40 00 00 11 C5 50 00 08 8F AA 4E CE 33 C0 80 87 00 00 00 00 00
					39 00 00 40 00 00 02 6F 25
					39 00 00 40 00 00 08 C5 00 01 07 AA 4D 57 00
					39 00 00 40 00 00 16 C6 B4 00 00 01 01 B9 00 2A 3F FF FC 58 00 00 12 48 00 00 00 00 00
					39 00 00 40 00 00 02 6F 15
					39 00 00 40 00 00 11 C6 05 00 90 C3 AA CE D3 33 C0 FB 33 00 00 00 00 00
					39 00 00 40 00 00 02 6F 25
					39 00 00 40 00 00 08 C6 00 88 90 AA CF D3 00
					39 00 00 40 00 00 16 C7 31 00 05 A4 05 A4 00 00 3F FE 53 50 3F FE 53 50 00 00 1F D1 10
					39 00 00 40 00 00 02 6F 15
					39 00 00 40 00 00 11 C7 0B 22 55 7B 00 2C 52 33 F0 DA DA 05 A4 00 00 00
					39 00 00 40 00 00 02 6F 25
					39 00 00 40 00 00 08 C7 44 F0 F7 AA 4D 54 00
					39 00 00 40 00 00 16 C8 3D 00 05 A4 05 A4 00 00 3F FE 53 50 00 00 00 00 00 00 00 00 00
					39 00 00 40 00 00 02 6F 15
					39 00 00 40 00 00 11 C8 1A 22 55 7B 00 53 79 33 C0 DA 26 00 00 00 00 00
					39 00 00 40 00 00 02 6F 25
					39 00 00 40 00 00 08 C8 44 69 70 AA CF D3 00
					39 00 00 40 00 00 16 C9 27 00 05 A4 05 A4 00 00 00 00 00 00 3F FE 53 50 00 00 00 00 00
					39 00 00 40 00 00 02 6F 15
					39 00 00 40 00 00 11 C9 0B 22 7C A2 00 2C 52 33 30 26 DA 00 00 00 00 00
					39 00 00 40 00 00 02 6F 25
					39 00 00 40 00 00 08 C9 00 00 00 00 00 00 00
					39 00 00 40 00 00 16 CA 2B 00 05 A4 05 A4 00 00 00 00 00 00 00 00 00 00 7F FF E0 2E F0
					39 00 00 40 00 00 02 6F 15
					39 00 00 40 00 00 11 CA 1A 22 7C A2 00 53 79 33 0F 26 26 FA 5C 00 00 00
					39 00 00 40 00 00 02 6F 25
					39 00 00 40 00 00 08 CA 00 00 00 00 00 00 00
					39 00 00 40 00 00 16 CB 00 00 00 00 00 00 00 00 00 00 00 00 00 00 00 00 00 00 00 00 00
					39 00 00 40 00 00 02 6F 15
					39 00 00 40 00 00 11 CB 00 00 00 00 00 00 00 00 00 00 00 00 00 00 00 00
					39 00 00 40 00 00 02 6F 25
					39 00 00 40 00 00 08 CB 00 00 00 00 00 00 00
					39 00 00 40 00 00 16 CC 00 00 00 00 00 00 00 00 00 00 00 00 00 00 00 00 00 00 00 00 00
					39 00 00 40 00 00 02 6F 15
					39 00 00 40 00 00 11 CC 00 00 00 00 00 00 00 00 00 00 00 00 00 00 00 00
					39 00 00 40 00 00 02 6F 25
					39 00 00 40 00 00 08 CC 00 00 00 00 00 00 00
					39 00 00 40 00 00 16 CD 00 00 00 00 00 00 00 00 00 00 00 00 00 00 00 00 00 00 00 00 00
					39 00 00 40 00 00 02 6F 15
					39 00 00 40 00 00 11 CD 00 00 00 00 00 00 00 00 00 00 00 00 00 00 00 00
					39 00 00 40 00 00 02 6F 25
					39 00 00 40 00 00 08 CD 00 00 00 00 00 00 00
					39 00 00 40 00 00 16 CE 00 00 00 00 00 00 00 00 00 00 00 00 00 00 00 00 00 00 00 00 00
					39 00 00 40 00 00 02 6F 15
					39 00 00 40 00 00 11 CE 00 00 00 00 00 00 00 00 00 00 00 00 00 00 00 00
					39 00 00 40 00 00 02 6F 25
					39 00 00 40 00 00 08 CE 00 00 00 00 00 00 00
					39 00 00 40 00 00 16 CF 00 00 00 00 00 00 00 00 00 00 00 00 00 00 00 00 00 00 00 00 00
					39 00 00 40 00 00 02 6F 15
					39 00 00 40 00 00 11 CF 00 00 00 00 00 00 00 00 00 00 00 00 00 00 00 00
					39 00 00 40 00 00 02 6F 25
					39 00 00 40 00 00 08 CF 00 00 00 00 00 00 00
					39 00 00 40 00 00 16 D0 00 00 00 00 00 00 00 00 00 00 00 00 00 00 00 00 00 00 00 00 00
					39 00 00 40 00 00 02 6F 15
					39 00 00 40 00 00 11 D0 00 00 00 00 00 00 00 00 00 00 00 00 00 00 00 00
					39 00 00 40 00 00 02 6F 25
					39 00 00 40 00 00 08 D0 00 00 00 00 00 00 00
					39 00 00 40 00 00 0F D1 80 00 00 00 00 04 F8 80 00 6B BD 09 04 F7
					39 00 00 40 00 00 02 6F 0E
					39 00 00 40 00 00 0F D1 80 00 00 00 00 04 F7 FF FF DD B9 00 04 F7
					39 00 00 40 00 00 02 6F 1C
					39 00 00 40 00 00 0F D1 FF E3 8B 46 00 04 F7 FF FF FF 4F B1 04 F8
					39 00 00 40 00 00 02 6F 2A
					39 00 00 40 00 00 0C D1 00 00 00 00 00 04 F8 7F FF E0 2E
					39 00 00 40 00 00 12 D2 F0 04 F8 00 00 1F D1 10 04 F8 00 00 00 00 00 04 F8
					//RCN
					39 00 00 40 00 00 06 F0 55 AA 52 08 07
					39 00 00 40 00 00 02 C0 A7
					//OSC trim
					39 00 00 40 00 00 06 F0 55 AA 52 08 01
					39 00 00 40 00 00 36 C3 99 29 02 6B 19 00 29 00 6B 19 00 3F 5A 08 3F 1A D4 3F 2A 07 3F 28 D4 3F 25 06 3F 61 D4 3F 3B 46 3F 46 07 3F 5A 08 3F 1A D4 11 11 01 00 10 00 77 00 AA 02 AA 02
					39 00 00 40 00 00 06 F0 55 AA 52 08 01
					39 00 00 40 00 00 07 B3 44 44 44 44 44 44
					39 00 00 40 00 00 06 F0 55 AA 52 08 07
					39 00 00 40 00 00 0E B4 C0 50 60 60 50 35 80 20 60 58 80 38 70
					//OD
					39 00 00 40 00 00 06 F0 55 AA 52 08 08
					39 00 00 40 00 00 05 E0 01 01 81 01
					39 00 00 40 00 00 02 6F 06
					39 00 00 40 00 00 0E E0 80 00 21 32 43 54 65 66 66 76 87 98 99
					39 00 00 40 00 00 06 F0 55 AA 52 08 08
					39 00 00 40 00 00 02 6F 04
					39 00 00 40 00 00 02 E0 20
					39 00 00 40 00 00 02 6F 1B
					39 00 00 40 00 00 04 EB 44 00 00
					39 00 00 40 00 00 02 6F 1E
					39 00 00 40 00 00 04 EB 94 00 00
					39 00 00 40 00 00 02 6F 21
					39 00 00 40 00 00 03 EB 04 00
					39 00 00 40 00 00 02 6F 24
					39 00 00 40 00 00 04 EB 10 32 54
					39 00 00 40 00 00 0F E1 03 04 20 00 00 00 00 00 00 00 00 00 00 00
					39 00 00 40 00 00 0F E2 03 04 20 00 00 00 00 00 00 00 00 00 00 00
					39 00 00 40 00 00 0F E3 00 00 00 00 00 00 00 00 00 00 00 00 00 00
					39 00 00 40 00 00 02 6F 0E
					39 00 00 40 00 00 0F E1 02 04 17 03 03 03 03 03 03 03 03 08 0F 1A
					39 00 00 40 00 00 02 6F 0E
					39 00 00 40 00 00 0F E2 03 04 1A 03 03 03 03 03 03 03 03 09 0E 17
					39 00 00 40 00 00 02 6F 0E
					39 00 00 40 00 00 0F E3 03 04 06 03 03 03 03 03 03 04 03 09 0E 07
					39 00 00 40 00 00 02 6F 1C
					39 00 00 40 00 00 0F E1 01 03 0F 03 03 03 03 03 03 03 03 03 08 0F
					39 00 00 40 00 00 02 6F 1C
					39 00 00 40 00 00 0F E2 02 03 12 04 04 04 04 04 04 04 04 04 07 0C
					39 00 00 40 00 00 02 6F 1C
					39 00 00 40 00 00 0F E3 02 03 05 04 04 04 04 04 04 04 04 03 07 12
					39 00 00 40 00 00 02 6F 2A
					39 00 00 40 00 00 0F E1 01 03 0C 04 04 04 04 04 04 04 04 04 07 0E
					39 00 00 40 00 00 02 6F 2A
					39 00 00 40 00 00 0F E2 02 03 0D 03 03 03 03 03 03 03 03 03 06 0D
					39 00 00 40 00 00 02 6F 2A
					39 00 00 40 00 00 0F E3 01 01 04 03 03 03 03 03 03 03 03 05 0B 13
					39 00 00 40 00 00 02 6F 38
					39 00 00 40 00 00 0F E1 02 04 07 04 04 04 04 04 04 04 04 09 10 1A
					39 00 00 40 00 00 02 6F 38
					39 00 00 40 00 00 0F E2 03 04 08 04 04 04 04 04 04 04 04 05 09 11
					39 00 00 40 00 00 02 6F 38
					39 00 00 40 00 00 0F E3 01 01 03 04 04 04 04 04 04 04 05 05 0A 13
					39 00 00 40 00 00 02 6F 46
					39 00 00 40 00 00 0F E1 02 04 03 03 03 03 03 03 05 05 05 05 05 10
					39 00 00 40 00 00 02 6F 46
					39 00 00 40 00 00 0F E2 03 04 04 03 03 03 03 03 04 04 04 04 04 06
					39 00 00 40 00 00 02 6F 46
					39 00 00 40 00 00 0F E3 01 01 04 03 03 03 03 03 04 04 04 04 04 06
					39 00 00 40 00 00 02 6F 54
					39 00 00 40 00 00 0F E1 01 01 01 04 05 05 05 03 03 03 02 02 02 02
					39 00 00 40 00 00 02 6F 54
					39 00 00 40 00 00 0F E2 01 02 02 04 04 05 05 02 02 01 01 01 01 01
					39 00 00 40 00 00 02 6F 54
					39 00 00 40 00 00 0F E3 00 00 00 02 04 05 05 02 02 01 01 01 01 01
					39 00 00 40 00 00 02 6F 62
					39 00 00 40 00 00 0F E1 01 02 02 04 04 04 04 03 03 03 02 02 02 02
					39 00 00 40 00 00 02 6F 62
					39 00 00 40 00 00 0F E2 01 02 02 03 03 03 03 02 02 01 01 01 01 01
					39 00 00 40 00 00 02 6F 62
					39 00 00 40 00 00 0F E3 00 00 00 03 03 03 03 02 02 01 01 01 01 01
					39 00 00 40 00 00 02 6F 70
					39 00 00 40 00 00 0F E1 01 02 02 04 04 04 04 03 03 03 02 02 02 02
					39 00 00 40 00 00 02 6F 70
					39 00 00 40 00 00 0F E2 01 02 02 04 05 04 04 02 02 02 01 01 01 01
					39 00 00 40 00 00 02 6F 70
					39 00 00 40 00 00 0F E3 00 00 00 04 05 04 04 02 02 02 01 01 01 01
					// Sleep out
					15 00 00 00 78 00 02 11 00
					// Display on
					15 00 00 00 00 00 02 29 00
					39 00 00 40 00 00 02 68 00
					39 00 00 40 00 00 06 F0 55 AA 52 08 00
					39 00 00 40 00 00 02 6F 04
					39 00 00 40 00 00 02 B1 00
					39 00 00 40 00 00 02 6F 2A
					39 00 00 40 00 00 02 BB 00
					39 00 00 40 00 00 02 6F 30
					39 00 00 40 00 00 02 C0 3F
					39 00 00 40 00 00 06 F0 55 AA 52 08 09
					39 00 00 40 00 00 02 BD 04
					39 00 00 40 00 00 02 6F 01
					39 00 00 40 00 00 0A BD 31 9D 25 54 13 14 A6 98 E2
					39 00 00 40 00 00 02 6F 0A
					39 00 00 40 00 00 06 BD 10 20 40 80 FF
					39 00 00 40 00 00 02 6F 1A
					39 00 00 40 00 00 06 BD FF FF FF FF FF
					39 00 00 40 00 00 02 6F 10
					39 00 00 40 00 00 04 BD FD 07 00
					39 00 00 40 00 00 02 6F 16
					39 00 00 40 00 00 02 BD 15
					39 00 00 40 00 00 06 F0 55 AA 52 08 09
					39 00 00 40 00 00 02 6F 00
					39 00 00 40 00 00 1F BE 19 14 0A 23 1E 05 05 00 05 0A 01 01 03 06 82 00 02 02 00 09 81 02 80 88 0B 01 00 00 07 81
					39 00 00 40 00 00 02 6F 1E
					39 00 00 40 00 00 1F BE 19 14 0A 23 1E 05 05 00 05 0A 01 01 03 06 82 00 02 02 00 09 81 02 80 88 0B 01 00 00 07 81
					39 00 00 40 00 00 02 6F 3C
					39 00 00 40 00 00 1F BE 19 14 0A 23 1E 05 05 00 05 0A 01 01 03 06 82 00 02 02 00 09 81 02 80 88 0B 01 00 00 07 81
					39 00 00 40 00 00 06 F0 55 AA 52 08 09
					39 00 00 40 00 00 02 6F 00
					39 00 00 40 00 00 1F BF 19 18 0C 18 2C 08 02 02 0A 04 04 04 10 08 14 01 04 06 00 0C 00 00 04 89 88 02 02 05 02 0A
					39 00 00 40 00 00 02 6F 1E
					39 00 00 40 00 00 1F BF 19 18 0C 18 2C 08 02 02 0A 04 04 04 10 08 14 01 04 06 00 0C 00 00 04 89 88 02 02 05 02 0A
					39 00 00 40 00 00 02 6F 3C
					39 00 00 40 00 00 1F BF 19 18 0C 18 2C 08 02 02 0A 04 04 04 10 08 14 01 04 06 00 0C 00 00 04 89 88 02 02 05 02 0A
					// 165Hz Freq. Setting
					39 00 00 40 00 00 2D A9 01 00 44 26 27 00 00 01 00 44 28 2C 00 00 08 0B 38 02 01 C3 23 25 3F 3B 46 02 01 C3 26 27 3F 46 02 01 C3 28 28 07 02 01 C3 2E 2E 01
					39 00 00 40 00 00 B5 A9 02 08 E0 00 00 00 02 08 E1 02 02 20 02 08 E2 02 02 20 02 08 E1 10 10 17 02 08 E2 10 10 1A 02 08 E1 1E 1E 0F 02 08 E2 1E 1E 12 02 08 E1 2C 2C 0C 02 08 E2 2C 2C 0D 02 08 E1 3A 3A 07 02 08 E2 3A 3A 08 02 08 E3 3A 3A 03 02 08 E1 43 45 09 10 1A 02 08 E2 43 45 05 09 11 02 08 E3 43 45 05 0A 13 02 08 E1 48 48 03 02 08 E2 48 48 04 02 08 E3 48 48 04 02 08 E1 55 56 01 01 02 08 E2 56 56 02 02 08 E3 55 56 00 00 02 08 E1 64 64 02 02 08 E2 64 64 02 02 08 E3 62 64 00 00 00 02 08 E1 72 72 02 02 08 E2 72 72 02 02 08 E3 70 72 00 00 00 02 08 E0 00 00 01
					39 00 00 00 00 00 91 A9 01 00 68 00 00 00 02 01 DD 02 03 04 85 02 04 B5 01 03 00 00 86 01 00 9D 00 00 AA 02 08 B0 00 00 00 01 00 A2 00 47 13 02 09 BD 00 00 04 00 00 00 00 00 00 00 02 08 B7 20 27 09 3E 09 3E 0B 03 0B 03 02 08 B7 28 2D 0B 5A 0B 5A 0B 09 00 00 02 08 B0 00 00 00 00 00 00 00 00 00 00 01 00 2F 00 00 03 00 00 00 00 00 00 00 02 01 B9 1F 1F 4A 01 00 8D 02 02 01 01 00 A3 00 0F 82 00 00 00 00 02 01 B9 1F 1F 4A 00 00 00 00 00 01 00 A3 10 11 00 00
				];

			};
		};
	};
};

&soc {
	dsi_panel_AE106_P_1_A0037_dsc_cmd {
		qcom,dsi-display-active;
	};
};

&dsi_panel_AE106_P_1_A0037_dsc_cmd {
	qcom,panel-supply-entries = <&oplus_dsi_panel_custom_pwr_supply>;
	qcom,platform-te-gpio = <&tlmm 86 0>;
	qcom,platform-reset-gpio = <&tlmm 146 0>;
	/* OLED_PMIC_RST */
	oplus,panel-gpio1 = <&pm8550ve_i_gpios 3 0>;
	/* VDDR_1P2_EN */
	oplus,panel-gpio2 = <&pm8550ve_i_gpios 4 0>;

	oplus,panel-reset-position = <0x02>;
	oplus,panel-power-on-sequence = "1", "gpio1", "1", "vddio", "3", "vci", "3", "gpio2", "10";
	oplus,panel-power-off-sequence = "1", "gpio2", "3", "vci", "3", "vddio", "3", "gpio1", "1";

	//enable mipi strength
	oplus,enhance_mipi_strength;

	/* BRIGHTNESS CONFIG */
	qcom,mdss-dsi-bl-pmic-control-type = "bl_ctrl_dcs";
	qcom,bl-update-flag = "delay_until_first_frame";
	qcom,mdss-dsi-bl-inverted-dbv;
	qcom,mdss-dsi-bl-min-level = <1>;
	qcom,mdss-dsi-bl-max-level = <4094>;
	qcom,mdss-brightness-max-level = <4094>;
	oplus,dsi-bl-normal-max-level = <3545>;
	oplus,dsi-brightness-normal-max-level = <3545>;
	oplus,dsi-dc-backlight-threshold = <1960>;
	oplus,dsi-brightness-default-level = <1269>;

	/* ESD CONFIG */
	qcom,esd-check-enabled;
	oplus,esd-check-flag-enabled;
	qcom,mdss-dsi-panel-status-check-mode = "reg_read";
	qcom,mdss-dsi-panel-status-command = [
			06 00 00 00 00 00 01 0A
		];
	qcom,mdss-dsi-panel-status-command-state = "dsi_lp_mode";
	qcom,mdss-dsi-panel-status-value = <
			0x9C
	>;
	qcom,mdss-dsi-panel-status-read-length = <1>;
	oplus,mdss-dsi-panel-status-match-modes = <0x00000000>;

	/* FACTORY CONFIG */
	oplus,mdss-dsi-vendor-name = "A0037";
	oplus,mdss-dsi-manufacture = "P_1";
	oplus,color_vivid_status;
	oplus,color_srgb_status;
	/* oplus,color_softiris_status; */
	oplus,color_oplus_calibrate_status;
	oplus,color_dual_brightness_status;
	oplus,color_2nit_status;
	oplus,color_loading_status;
	/* oplus,color_nature_profession_status; */
	oplus,mdss-dsi-panel-type = <1>;

	/* OPLUS FEATURES CONFIG */
	oplus,dsi-serial-number-enabled;
	oplus,dsi-serial-number-switch-page;
	oplus,dsi-serial-number-index= <0>;
	oplus,dsi-serial-number-reg= <0xD7>;
	oplus,dsi-serial-number-read-count= <7>;
	oplus,dsi-serial-number-base-year = <2020>;
	qcom,ulps-enabled;
	qcom,dsi-select-clocks = "pll_byte_clk0", "pll_dsi_clk0";

	oplus,panel-all-timing-switch-frame-delay;

	oplus,dsi-lut-set-enabled;
	oplus,vreg_ctrl_flag;
	oplus,wait-te-config = <0x00000004>;

	/* ofp config */
	oplus,ofp-fp-type = <0x40>;
	oplus,ofp-longrui-aod-config = <0x06>;
	oplus,ofp-need-to-wait-data-before-aod-on;
	oplus,ofp-aod-off-frame-cost = <1>;
	oplus,panel-ae174-gamma-compensation-support;
	/* adfr config */
	// oplus,adfr-config = <0xe51>;  // 0b0000'0000'0101'0001
	// oplus,adfr-test-te-gpio = <&tlmm 85 0>;
	/* just for qsync enable*/
	//qcom,qsync-enable;
	//qcom,mdss-dsi-qsync-min-refresh-rate = <30>;

	/*OPLUS_FEATURE_AP_UIR_DIMMING*/
	/*oplus,apuir-up800nit-ds-list   = <DX1X0   DS1X3   DS2X0>;*/
	/*oplus,apuir-less800nit-ds-list = <DX1X0   DS1X3>;*/
	oplus,apuir-up800nit-ds-list   = <2988   3320   4095>;
	oplus,apuir-less800nit-ds-list = <2988   3367>;
	oplus,apuir-sdc-band;

	// qcom,dsi-dyn-clk-enable;
};

&dsi_panel_AE106_P_1_A0037_dsc_cmd {
	qcom,mdss-dsi-display-timings {
		timing@sdc_fhd_120 { /* FHD+ 120hz 1152 Mbps */
			qcom,mdss-dsi-panel-phy-timings = [00 26 0A 0A 1B 19 0A 0A 0A 02 04 00 20 0F];
			qcom,display-topology = <1 1 1>,<2 2 1>;
			qcom,default-topology-index = <1>;
			qcom,dsi-mode-te-width-us = <224>;
		};
		timing@sdc_fhd_90 { /* FHD+ 90hz  1152 Mbps */
			qcom,mdss-dsi-panel-phy-timings = [00 26 0A 0A 1B 19 0A 0A 0A 02 04 00 20 0F];
			qcom,display-topology = <1 1 1>,<2 2 1>;
			qcom,default-topology-index = <1>;
			qcom,dsi-mode-te-width-us = <3100>;
		};
		timing@sdc_fhd_60 { /* FHD+ 60hz 1152 Mbps */
			qcom,mdss-dsi-panel-phy-timings = [00 26 0A 0A 1B 19 0A 0A 0A 02 04 00 20 0F];
			qcom,display-topology = <1 1 1>,<2 2 1>;
			qcom,default-topology-index = <1>;
			qcom,dsi-mode-te-width-us = <8700>;
		};
		timing@sdc_fhd_144 { /* FHD+ 144hz 1152 Mbps */
			qcom,mdss-dsi-panel-phy-timings = [00 26 0A 0A 1B 19 0A 0A 0A 02 04 00 20 0F];
			qcom,display-topology = <1 1 1>,<2 2 1>;
			qcom,default-topology-index = <1>;
			qcom,dsi-mode-te-width-us = <225>;
		};
		timing@sdc_fhd_165 { /* FHD+ 165hz 1434 Mbps */
			qcom,mdss-dsi-panel-phy-timings = [00 2E 0C 0C 1D 1B 0C 0D 0B 02 04 00 25 11];
			qcom,display-topology = <1 1 1>,<2 2 1>;
			qcom,default-topology-index = <1>;
			qcom,dsi-mode-te-width-us = <227>;
		};
	};
};

&dsi_panel_AE106_P_1_A0037_dsc_cmd {
	qcom,panel_voltage_vddi_name = "vddio";
	qcom,panel_voltage_vddi = <0 1800000 1850000 1950000>;
	qcom,panel_voltage_vddr_name = "vddio";
	qcom,panel_voltage_vddr = <1 1800000 1850000 1950000>;
};

&dsi_panel_AE106_P_1_A0037_dsc_cmd {
	/* demura dbv config */

	/* pwm config */
	/*	oplus,pwm-switch-config:
		Bit0: pwm feature enable
		Bit1: pwm mode switch enable, need to config switch cmds
		Bit2: force enabled pwm mode switch cmd, will send mode cmd even dbv threshold cmd feature is configed
		Bit3: pwm dbv threshold pulse switch enable, need to config threshold switch cmds
		Bit4: wait te before sending pwm dbv threshold pulse switch cmd
		Bit5: replace specific cmd to other cmd while in pwm 1pulse mode
		Bit6: sending extend cmd while panel power on accroding to current pwm mode
		Bit7: sending extend cmd while timing switch accroding to current pwm pulse level
		Bit8: sending extend cmd after sending dbv threshold cmd in another thread
		...
		Bit24:support pwm mode0
		Bit25:support pwm mode1
		Bit26:support pwm mode2
	*/
	oplus,pwm-switch-config = <0x01000001>;
	/*	oplus,pwm-switch-mode0-states-info/oplus,pwm-switch-mode1-states-info:
		Specific dbv threshold and pulse info of 2 pwm mode, for pulse, 0 symbols 1pulse,
		1symbols 3pulse and 2 symbols 18pulse. The format should be 1 dbv threshold info with
		2 pwm pulse levels left and right(for example, <2 1087 1> means 18pulse while dbv <= 1087
		and 3pulse while dbv > 1087), or only one pulse level, no threshold.
	*/
	oplus,pwm-switch-mode0-states-info = <0>;

	/*	oplus,pwm-mode1-cmd-switch-map/oplus,pwm-mode2-cmd-switch-map;
		Specific cmd replace relationship while in switch on(1pulse) mode. It is a string array that
		compose with cmd names, every 2 names combine 1 map. For example, map "'a', 'b'" means replace
		a to b while sending a in switch on mode.
	*/
	//oplus,pwm-mode2-cmd-switch-map = "qcom,mdss-dsi-nolp-command", "qcom,mdss-dsi-aod-off-pwm-mode2-command",
	//		"qcom,mdss-dsi-timing-switch-command", "qcom,mdss-dsi-timming-switch-pwm-mode2-command";

};
